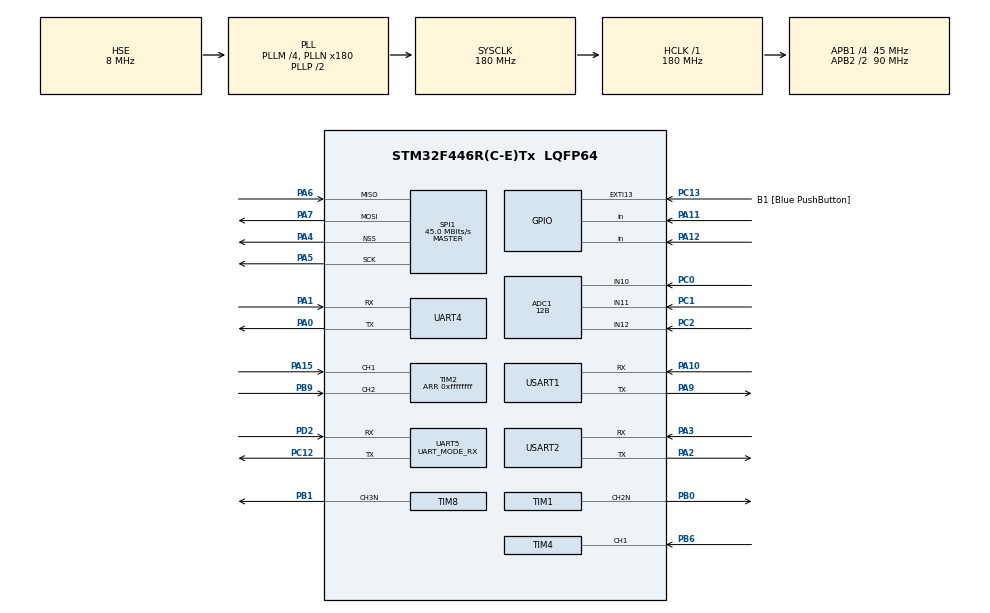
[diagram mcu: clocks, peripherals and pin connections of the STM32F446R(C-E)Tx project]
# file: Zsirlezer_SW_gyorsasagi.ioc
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ADC1.Channel-0\#ChannelRegularConversion=ADC_CHANNEL_10
ADC1.ClockPrescaler=ADC_CLOCK_SYNC_PCLK_DIV4
ADC1.ContinuousConvMode=DISABLE
ADC1.DMAContinuousRequests=ENABLE
ADC1.DataAlign=ADC_DATAALIGN_RIGHT
ADC1.DiscontinuousConvMode=DISABLE
ADC1.EOCSelection=ADC_EOC_SINGLE_CONV
ADC1.EnableAnalogWatchDog=false
ADC1.ExternalTrigConvEdge=ADC_EXTERNALTRIGCONVEDGE_NONE
ADC1.InjNumberOfConversion=0
ADC1.NbrOfConversion=1
ADC1.NbrOfConversionFlag=1
ADC1.Rank-0\#ChannelRegularConversion=1
ADC1.Resolution=ADC_RESOLUTION_12B
ADC1.SamplingTime-0\#ChannelRegularConversion=ADC_SAMPLETIME_15CYCLES
ADC1.ScanConvMode=ENABLE
ADC1.master=1
Dma.ADC1.3.Direction=DMA_PERIPH_TO_MEMORY
Dma.ADC1.3.FIFOMode=DMA_FIFOMODE_DISABLE
Dma.ADC1.3.Instance=DMA2_Stream0
Dma.ADC1.3.MemDataAlignment=DMA_MDATAALIGN_HALFWORD
Dma.ADC1.3.MemInc=DMA_MINC_ENABLE
Dma.ADC1.3.Mode=DMA_CIRCULAR
Dma.ADC1.3.PeriphDataAlignment=DMA_PDATAALIGN_HALFWORD
Dma.ADC1.3.PeriphInc=DMA_PINC_DISABLE
Dma.ADC1.3.Priority=DMA_PRIORITY_LOW
Dma.Request0=UART5_RX
Dma.Request1=USART1_RX
Dma.Request2=USART1_TX
Dma.Request3=ADC1
Dma.Request4=USART2_TX
Dma.UART5_RX.0.Direction=DMA_PERIPH_TO_MEMORY
Dma.UART5_RX.0.FIFOMode=DMA_FIFOMODE_DISABLE
Dma.UART5_RX.0.Instance=DMA1_Stream0
Dma.UART5_RX.0.MemDataAlignment=DMA_MDATAALIGN_BYTE
Dma.UART5_RX.0.MemInc=DMA_MINC_ENABLE
Dma.UART5_RX.0.Mode=DMA_CIRCULAR
Dma.UART5_RX.0.PeriphDataAlignment=DMA_PDATAALIGN_BYTE
Dma.UART5_RX.0.PeriphInc=DMA_PINC_DISABLE
Dma.UART5_RX.0.Priority=DMA_PRIORITY_LOW
Dma.USART1_RX.1.Direction=DMA_PERIPH_TO_MEMORY
Dma.USART1_RX.1.FIFOMode=DMA_FIFOMODE_DISABLE
Dma.USART1_RX.1.Instance=DMA2_Stream2
Dma.USART1_RX.1.MemDataAlignment=DMA_MDATAALIGN_BYTE
Dma.USART1_RX.1.MemInc=DMA_MINC_ENABLE
Dma.USART1_RX.1.Mode=DMA_CIRCULAR
Dma.USART1_RX.1.PeriphDataAlignment=DMA_PDATAALIGN_BYTE
Dma.USART1_RX.1.PeriphInc=DMA_PINC_DISABLE
Dma.USART1_RX.1.Priority=DMA_PRIORITY_LOW
Dma.USART1_TX.2.Direction=DMA_MEMORY_TO_PERIPH
Dma.USART1_TX.2.FIFOMode=DMA_FIFOMODE_DISABLE
Dma.USART1_TX.2.Instance=DMA2_Stream7
Dma.USART1_TX.2.MemDataAlignment=DMA_MDATAALIGN_BYTE
Dma.USART1_TX.2.MemInc=DMA_MINC_ENABLE
Dma.USART1_TX.2.Mode=DMA_NORMAL
Dma.USART1_TX.2.PeriphDataAlignment=DMA_PDATAALIGN_BYTE
Dma.USART1_TX.2.PeriphInc=DMA_PINC_DISABLE
Dma.USART1_TX.2.Priority=DMA_PRIORITY_LOW
Dma.USART2_TX.4.Direction=DMA_MEMORY_TO_PERIPH
Dma.USART2_TX.4.FIFOMode=DMA_FIFOMODE_DISABLE
Dma.USART2_TX.4.Instance=DMA1_Stream6
Dma.USART2_TX.4.MemDataAlignment=DMA_MDATAALIGN_BYTE
Dma.USART2_TX.4.MemInc=DMA_MINC_ENABLE
Dma.USART2_TX.4.Mode=DMA_NORMAL
Dma.USART2_TX.4.PeriphDataAlignment=DMA_PDATAALIGN_BYTE
Dma.USART2_TX.4.PeriphInc=DMA_PINC_DISABLE
Dma.USART2_TX.4.Priority=DMA_PRIORITY_LOW
Mcu.Family=STM32F4
Mcu.Name=STM32F446R(C-E)Tx
Mcu.Package=LQFP64
NVIC.DMA1_Stream0_IRQn=true\:0\:0\:false\:false\:true
NVIC.DMA1_Stream6_IRQn=true\:0\:0\:false\:false\:true
NVIC.DMA2_Stream0_IRQn=true\:0\:0\:false\:false\:true
NVIC.DMA2_Stream2_IRQn=true\:0\:0\:false\:false\:true
NVIC.DMA2_Stream7_IRQn=true\:0\:0\:false\:false\:true
NVIC.PriorityGroup=NVIC_PRIORITYGROUP_0
NVIC.TIM4_IRQn=true\:0\:0\:false\:false\:true
NVIC.TIM6_DAC_IRQn=true\:0\:0\:false\:false\:true
NVIC.TIM7_IRQn=true\:0\:0\:false\:false\:true
NVIC.UART4_IRQn=true\:0\:0\:false\:false\:true
NVIC.UART5_IRQn=true\:0\:0\:false\:false\:true
NVIC.USART1_IRQn=true\:0\:0\:false\:false\:true
NVIC.USART2_IRQn=true\:0\:0\:false\:false\:true
PA0-WKUP.Mode=Asynchronous
PA0-WKUP.Signal=UART4_TX
PA1.Mode=Asynchronous
PA1.Signal=UART4_RX
PA10.Mode=Asynchronous
PA10.Signal=USART1_RX
PA11.Signal=GPIO_Input
PA12.Signal=GPIO_Input
PA13.GPIO_Label=TMS
PA13.Signal=SYS_JTMS-SWDIO
PA14.GPIO_Label=TCK
PA14.Signal=SYS_JTCK-SWCLK
PA15.Signal=S_TIM2_CH1_ETR
PA2.Mode=Asynchronous
PA2.Signal=USART2_TX
PA3.Mode=Asynchronous
PA3.Signal=USART2_RX
PA4.Mode=NSS_Signal_Hard_Output
PA4.Signal=SPI1_NSS
PA5.Mode=Full_Duplex_Master
PA5.Signal=SPI1_SCK
PA6.Mode=Full_Duplex_Master
PA6.Signal=SPI1_MISO
PA7.Mode=Full_Duplex_Master
PA7.Signal=SPI1_MOSI
PA9.Mode=Asynchronous
PA9.Signal=USART1_TX
PB0.GPIO_ModeDefaultPP=GPIO_MODE_AF_PP
PB0.Mode=PWM Generation2 CH2N
PB0.Signal=TIM1_CH2N
PB1.Mode=PWM Generation3 CH3N
PB1.Signal=TIM8_CH3N
PB3.GPIO_Label=SWO
PB3.Signal=SYS_JTDO-SWO
PB6.Signal=S_TIM4_CH1
PB9.Signal=S_TIM2_CH2
PC0.Signal=ADCx_IN10
PC1.Signal=ADCx_IN11
PC12.Mode=Asynchronous
PC12.Signal=UART5_TX
PC13.GPIO_Label=B1 [Blue PushButton]
PC13.GPIO_ModeDefaultEXTI=GPIO_MODE_EVT_RISING
PC13.Signal=GPXTI13
PC2.Signal=ADCx_IN12
PD2.Mode=Asynchronous
PD2.Signal=UART5_RX
PH0-OSC_IN.Mode=HSE-External-Oscillator
PH0-OSC_IN.Signal=RCC_OSC_IN
PH1-OSC_OUT.Mode=HSE-External-Oscillator
PH1-OSC_OUT.Signal=RCC_OSC_OUT
ProjectManager.HeapSize=0x200
ProjectManager.StackSize=0x400
ProjectManager.TargetToolchain=SW4STM32
RCC.AHBFreq_Value=180000000
RCC.APB1CLKDivider=RCC_HCLK_DIV4
RCC.APB1Freq_Value=45000000
RCC.APB1TimFreq_Value=90000000
RCC.APB2CLKDivider=RCC_HCLK_DIV2
RCC.APB2Freq_Value=90000000
RCC.APB2TimFreq_Value=180000000
RCC.CortexFreq_Value=180000000
RCC.FLatency-AdvancedSettings=FLASH_LATENCY_5
RCC.HCLKFreq_Value=180000000
RCC.HSE_VALUE=8000000
RCC.HSI_VALUE=16000000
RCC.LSE_VALUE=32768
RCC.PLLM=4
RCC.PLLN=180
RCC.PLLSourceVirtual=RCC_PLLSOURCE_HSE
RCC.SYSCLKFreq_VALUE=180000000
RCC.SYSCLKSource=RCC_SYSCLKSOURCE_PLLCLK
RCC.USBFreq_Value=180000000
RCC.VCOOutputFreq_Value=360000000
SH.ADCx_IN10.0=ADC1_IN10,IN10
SH.ADCx_IN11.0=ADC1_IN11,IN11
SH.ADCx_IN12.0=ADC1_IN12,IN12
SH.S_TIM2_CH1_ETR.0=TIM2_CH1,Encoder_Interface
SH.S_TIM2_CH2.0=TIM2_CH2,Encoder_Interface
SH.S_TIM4_CH1.0=TIM4_CH1,Input_Capture1_from_TI1
SPI1.CalculateBaudRate=45.0 MBits/s
SPI1.Mode=SPI_MODE_MASTER
SPI1.VirtualNSS=VM_NSSHARD
TIM1.Channel-PWM\ Generation2\ CH2N=TIM_CHANNEL_2
TIM1.Period=64614
TIM1.Prescaler=38
TIM1.Pulse-PWM\ Generation2\ CH2N=7497
TIM2.Period=0xffffffff
TIM4.ICPolarity_CH1=TIM_INPUTCHANNELPOLARITY_BOTHEDGE
TIM4.Period=64614
TIM4.Prescaler=38
TIM6.Period=65454
TIM6.Prescaler=65
TIM7.Period=9999
TIM7.Prescaler=89
TIM8.Channel-PWM\ Generation3\ CH3N=TIM_CHANNEL_3
TIM8.Period=64614
TIM8.Prescaler=38
TIM8.Pulse-PWM\ Generation3\ CH3N=6932
UART5.Mode=UART_MODE_RX
VP_TIM6_VS_ClockSourceINT.Mode=Enable_Timer
VP_TIM7_VS_ClockSourceINT.Mode=Enable_Timer
board=NUCLEO-F446RE

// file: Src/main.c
/**
  ******************************************************************************
  * File Name          : main.c
  * Description        : Main program body
  ******************************************************************************
  *
  * COPYRIGHT(c) 2017 STMicroelectronics
  *
  * Redistribution and use in source and binary forms, with or without modification,
  * are permitted provided that the following conditions are met:
  *   1. Redistributions of source code must retain the above copyright notice,
  *      this list of conditions and the following disclaimer.
  *   2. Redistributions in binary form must reproduce the above copyright notice,
  *      this list of conditions and the following disclaimer in the documentation
  *      and/or other materials provided with the distribution.
  *   3. Neither the name of STMicroelectronics nor the names of its contributors
  *      may be used to endorse or promote products derived from this software
  *      without specific prior written permission.
  *
  * THIS SOFTWARE IS PROVIDED BY THE COPYRIGHT HOLDERS AND CONTRIBUTORS "AS IS"
  * AND ANY EXPRESS OR IMPLIED WARRANTIES, INCLUDING, BUT NOT LIMITED TO, THE
  * IMPLIED WARRANTIES OF MERCHANTABILITY AND FITNESS FOR A PARTICULAR PURPOSE ARE
  * DISCLAIMED. IN NO EVENT SHALL THE COPYRIGHT HOLDER OR CONTRIBUTORS BE LIABLE
  * FOR ANY DIRECT, INDIRECT, INCIDENTAL, SPECIAL, EXEMPLARY, OR CONSEQUENTIAL
  * DAMAGES (INCLUDING, BUT NOT LIMITED TO, PROCUREMENT OF SUBSTITUTE GOODS OR
  * SERVICES; LOSS OF USE, DATA, OR PROFITS; OR BUSINESS INTERRUPTION) HOWEVER
  * CAUSED AND ON ANY THEORY OF LIABILITY, WHETHER IN CONTRACT, STRICT LIABILITY,
  * OR TORT (INCLUDING NEGLIGENCE OR OTHERWISE) ARISING IN ANY WAY OUT OF THE USE
  * OF THIS SOFTWARE, EVEN IF ADVISED OF THE POSSIBILITY OF SUCH DAMAGE.
  *
  ******************************************************************************
  */
#include "main.h"
#include "stm32f4xx_hal.h"
#include "adc.h"
#include "dma.h"
#include "spi.h"
#include "tim.h"
#include "usart.h"
#include "gpio.h"
#include "math.h"

/* USER CODE BEGIN Includes */
#include "stdbool.h"

//Defineok
//Vonalszam
#define NINCSVONAL 10
#define EGYVONAL 1
#define KETVONAL 2
#define HAROMVONAL 3
#define VONALHIBA 15

//Vonalobjektumok
#define GYORSITO 5
#define LASSITO 6
#define SIMA_VEZETOVONAL 13

//Sebszab
#define MEREDEKSEG_GYORSITASNAL 2000
#define MEREDEKSEG_LASSITASNAL 2000
#define ALAPJEL_MEREDEKSEG_GYORSITASNAL 3000
#define ALAPJEL_MEREDEKSEG_LASSITASNAL 3000

//Allapotteres szabalyozok
#define NORMAL 1
#define GYORSITO_SZAB 2

#define ELSOKOR 1
#define MASODIKKOR 2
#define HARMADIKKOR 3

/* USER CODE END Includes */

/* USER CODE BEGIN PV */
/* Private variables ---------------------------------------------------------*/

float atan_lut[5400] = {
	 -2233.6111,
	 -2233.155, -2232.6986, -2232.2421, -2231.7854, -2231.3285, -2230.8714, -2230.414, -2229.9565, -2229.4988, -2229.0408,
	 -2228.5827, -2228.1243, -2227.6658, -2227.207, -2226.7481, -2226.2889, -2225.8295, -2225.3699, -2224.9102, -2224.4502,
	 -2223.99, -2223.5296, -2223.069, -2222.6082, -2222.1471, -2221.6859, -2221.2245, -2220.7628, -2220.301, -2219.839,
	 -2219.3767, -2218.9142, -2218.4516, -2217.9887, -2217.5256, -2217.0623, -2216.5988, -2216.1351, -2215.6712, -2215.2071,
	 -2214.7428, -2214.2782, -2213.8135, -2213.3486, -2212.8834, -2212.418, -2211.9525, -2211.4867, -2211.0207, -2210.5545,
	 -2210.0881, -2209.6215, -2209.1546, -2208.6876, -2208.2204, -2207.7529, -2207.2852, -2206.8174, -2206.3493, -2205.881,
	 -2205.4125, -2204.9438, -2204.4749, -2204.0057, -2203.5364, -2203.0669, -2202.5971, -2202.1271, -2201.6569, -2201.1866,
	 -2200.7159, -2200.2451, -2199.7741, -2199.3029, -2198.8314, -2198.3598, -2197.8879, -2197.4158, -2196.9435, -2196.471,
	 -2195.9983, -2195.5254, -2195.0522, -2194.5789, -2194.1053, -2193.6315, -2193.1575, -2192.6833, -2192.2089, -2191.7343,
	 -2191.2594, -2190.7844, -2190.3091, -2189.8336, -2189.3579, -2188.882, -2188.4059, -2187.9296, -2187.453, -2186.9763,
	 -2186.4993, -2186.0221, -2185.5447, -2185.0671, -2184.5892, -2184.1112, -2183.6329, -2183.1544, -2182.6757, -2182.1968,
	 -2181.7177, -2181.2384, -2180.7588, -2180.279, -2179.799, -2179.3188, -2178.8384, -2178.3578, -2177.8769, -2177.3959,
	 -2176.9146, -2176.4331, -2175.9514, -2175.4694, -2174.9873, -2174.5049, -2174.0223, -2173.5395, -2173.0565, -2172.5733,
	 -2172.0898, -2171.6062, -2171.1223, -2170.6382, -2170.1538, -2169.6693, -2169.1845, -2168.6996, -2168.2144, -2167.729,
	 -2167.2433, -2166.7575, -2166.2714, -2165.7851, -2165.2986, -2164.8119, -2164.3249, -2163.8378, -2163.3504, -2162.8628,
	 -2162.375, -2161.8869, -2161.3986, -2160.9102, -2160.4215, -2159.9325, -2159.4434, -2158.954, -2158.4644, -2157.9746,
	 -2157.4846, -2156.9944, -2156.5039, -2156.0132, -2155.5223, -2155.0312, -2154.5398, -2154.0482, -2153.5564, -2153.0644,
	 -2152.5722, -2152.0797, -2151.587, -2151.0941, -2150.601, -2150.1076, -2149.6141, -2149.1203, -2148.6263, -2148.132,
	 -2147.6375, -2147.1429, -2146.6479, -2146.1528, -2145.6574, -2145.1619, -2144.6661, -2144.17, -2143.6738, -2143.1773,
	 -2142.6806, -2142.1837, -2141.6865, -2141.1891, -2140.6915, -2140.1937, -2139.6957, -2139.1974, -2138.6989, -2138.2002,
	 -2137.7012, -2137.2021, -2136.7027, -2136.203, -2135.7032, -2135.2031, -2134.7028, -2134.2023, -2133.7015, -2133.2005,
	 -2132.6993, -2132.1979, -2131.6962, -2131.1943, -2130.6922, -2130.1899, -2129.6873, -2129.1845, -2128.6815, -2128.1782,
	 -2127.6748, -2127.1711, -2126.6671, -2126.163, -2125.6586, -2125.154, -2124.6491, -2124.144, -2123.6387, -2123.1332,
	 -2122.6274, -2122.1215, -2121.6152, -2121.1088, -2120.6021, -2120.0952, -2119.5881, -2119.0807, -2118.5731, -2118.0653,
	 -2117.5572, -2117.049, -2116.5404, -2116.0317, -2115.5227, -2115.0135, -2114.5041, -2113.9944, -2113.4845, -2112.9744,
	 -2112.464, -2111.9534, -2111.4426, -2110.9316, -2110.4203, -2109.9088, -2109.397, -2108.8851, -2108.3728, -2107.8604,
	 -2107.3477, -2106.8348, -2106.3217, -2105.8083, -2105.2947, -2104.7809, -2104.2668, -2103.7525, -2103.238, -2102.7232,
	 -2102.2082, -2101.693, -2101.1775, -2100.6618, -2100.1459, -2099.6297, -2099.1133, -2098.5967, -2098.0798, -2097.5627,
	 -2097.0453, -2096.5278, -2096.01, -2095.4919, -2094.9736, -2094.4551, -2093.9364, -2093.4174, -2092.8982, -2092.3787,
	 -2091.859, -2091.3391, -2090.8189, -2090.2985, -2089.7779, -2089.257, -2088.7359, -2088.2146, -2087.693, -2087.1712,
	 -2086.6491, -2086.1268, -2085.6043, -2085.0815, -2084.5585, -2084.0353, -2083.5118, -2082.9881, -2082.4642, -2081.94,
	 -2081.4155, -2080.8909, -2080.366, -2079.8408, -2079.3154, -2078.7898, -2078.264, -2077.7379, -2077.2115, -2076.685,
	 -2076.1582, -2075.6311, -2075.1038, -2074.5763, -2074.0485, -2073.5205, -2072.9923, -2072.4638, -2071.935, -2071.4061,
	 -2070.8769, -2070.3474, -2069.8177, -2069.2878, -2068.7576, -2068.2272, -2067.6965, -2067.1657, -2066.6345, -2066.1031,
	 -2065.5715, -2065.0397, -2064.5076, -2063.9752, -2063.4426, -2062.9098, -2062.3767, -2061.8434, -2061.3099, -2060.7761,
	 -2060.242, -2059.7077, -2059.1732, -2058.6385, -2058.1034, -2057.5682, -2057.0327, -2056.497, -2055.961, -2055.4247,
	 -2054.8883, -2054.3516, -2053.8146, -2053.2774, -2052.7399, -2052.2023, -2051.6643, -2051.1261, -2050.5877, -2050.049,
	 -2049.5101, -2048.971, -2048.4316, -2047.8919, -2047.352, -2046.8119, -2046.2715, -2045.7309, -2045.19, -2044.6488,
	 -2044.1075, -2043.5659, -2043.024, -2042.4819, -2041.9395, -2041.3969, -2040.8541, -2040.311, -2039.7676, -2039.224,
	 -2038.6802, -2038.1361, -2037.5918, -2037.0472, -2036.5024, -2035.9573, -2035.412, -2034.8664, -2034.3206, -2033.7745,
	 -2033.2282, -2032.6816, -2032.1348, -2031.5877, -2031.0404, -2030.4929, -2029.9451, -2029.397, -2028.8487, -2028.3001,
	 -2027.7513, -2027.2023, -2026.6529, -2026.1034, -2025.5536, -2025.0035, -2024.4532, -2023.9027, -2023.3518, -2022.8008,
	 -2022.2495, -2021.6979, -2021.1461, -2020.594, -2020.0417, -2019.4891, -2018.9363, -2018.3833, -2017.8299, -2017.2764,
	 -2016.7225, -2016.1684, -2015.6141, -2015.0595, -2014.5047, -2013.9496, -2013.3943, -2012.8387, -2012.2828, -2011.7267,
	 -2011.1704, -2010.6138, -2010.0569, -2009.4998, -2008.9424, -2008.3848, -2007.8269, -2007.2688, -2006.7104, -2006.1518,
	 -2005.5929, -2005.0337, -2004.4743, -2003.9147, -2003.3548, -2002.7946, -2002.2342, -2001.6735, -2001.1126, -2000.5514,
	 -1999.99, -1999.4283, -1998.8663, -1998.3041, -1997.7416, -1997.1789, -1996.6159, -1996.0527, -1995.4892, -1994.9255,
	 -1994.3614, -1993.7972, -1993.2327, -1992.6679, -1992.1029, -1991.5376, -1990.972, -1990.4062, -1989.8402, -1989.2738,
	 -1988.7073, -1988.1404, -1987.5733, -1987.006, -1986.4384, -1985.8705, -1985.3024, -1984.734, -1984.1653, -1983.5964,
	 -1983.0273, -1982.4578, -1981.8882, -1981.3182, -1980.748, -1980.1775, -1979.6068, -1979.0358, -1978.4646, -1977.8931,
	 -1977.3213, -1976.7493, -1976.177, -1975.6045, -1975.0317, -1974.4586, -1973.8853, -1973.3117, -1972.7379, -1972.1637,
	 -1971.5894, -1971.0147, -1970.4398, -1969.8647, -1969.2893, -1968.7136, -1968.1376, -1967.5614, -1966.985, -1966.4082,
	 -1965.8312, -1965.254, -1964.6765, -1964.0987, -1963.5206, -1962.9423, -1962.3638, -1961.7849, -1961.2058, -1960.6265,
	 -1960.0468, -1959.467, -1958.8868, -1958.3064, -1957.7257, -1957.1447, -1956.5635, -1955.9821, -1955.4003, -1954.8183,
	 -1954.236, -1953.6535, -1953.0707, -1952.4876, -1951.9043, -1951.3207, -1950.7368, -1950.1527, -1949.5683, -1948.9836,
	 -1948.3987, -1947.8135, -1947.2281, -1946.6423, -1946.0563, -1945.4701, -1944.8835, -1944.2967, -1943.7097, -1943.1223,
	 -1942.5347, -1941.9469, -1941.3587, -1940.7703, -1940.1817, -1939.5927, -1939.0035, -1938.4141, -1937.8243, -1937.2343,
	 -1936.644, -1936.0535, -1935.4627, -1934.8716, -1934.2802, -1933.6886, -1933.0967, -1932.5045, -1931.9121, -1931.3194,
	 -1930.7264, -1930.1332, -1929.5397, -1928.9459, -1928.3519, -1927.7575, -1927.1629, -1926.5681, -1925.9729, -1925.3775,
	 -1924.7819, -1924.1859, -1923.5897, -1922.9932, -1922.3964, -1921.7994, -1921.2021, -1920.6045, -1920.0067, -1919.4086,
	 -1918.8102, -1918.2115, -1917.6126, -1917.0134, -1916.4139, -1915.8141, -1915.2141, -1914.6138, -1914.0132, -1913.4124,
	 -1912.8112, -1912.2098, -1911.6082, -1911.0062, -1910.404, -1909.8015, -1909.1988, -1908.5957, -1907.9924, -1907.3888,
	 -1906.785, -1906.1808, -1905.5764, -1904.9717, -1904.3668, -1903.7615, -1903.156, -1902.5503, -1901.9442, -1901.3379,
	 -1900.7312, -1900.1244, -1899.5172, -1898.9097, -1898.302, -1897.694, -1897.0858, -1896.4772, -1895.8684, -1895.2593,
	 -1894.6499, -1894.0403, -1893.4303, -1892.8201, -1892.2097, -1891.5989, -1890.9879, -1890.3765, -1889.7649, -1889.1531,
	 -1888.5409, -1887.9285, -1887.3158, -1886.7028, -1886.0895, -1885.476, -1884.8622, -1884.2481, -1883.6337, -1883.019,
	 -1882.4041, -1881.7889, -1881.1734, -1880.5576, -1879.9415, -1879.3252, -1878.7086, -1878.0917, -1877.4745, -1876.8571,
	 -1876.2393, -1875.6213, -1875.003, -1874.3844, -1873.7656, -1873.1464, -1872.527, -1871.9073, -1871.2873, -1870.6671,
	 -1870.0465, -1869.4257, -1868.8046, -1868.1832, -1867.5615, -1866.9395, -1866.3173, -1865.6948, -1865.072, -1864.4489,
	 -1863.8255, -1863.2019, -1862.5779, -1861.9537, -1861.3292, -1860.7044, -1860.0794, -1859.454, -1858.8284, -1858.2025,
	 -1857.5763, -1856.9498, -1856.323, -1855.696, -1855.0686, -1854.441, -1853.8131, -1853.1849, -1852.5564, -1851.9277,
	 -1851.2986, -1850.6693, -1850.0397, -1849.4098, -1848.7796, -1848.1491, -1847.5183, -1846.8873, -1846.256, -1845.6243,
	 -1844.9924, -1844.3603, -1843.7278, -1843.095, -1842.462, -1841.8286, -1841.195, -1840.5611, -1839.9269, -1839.2924,
	 -1838.6576, -1838.0226, -1837.3872, -1836.7516, -1836.1157, -1835.4795, -1834.843, -1834.2062, -1833.5691, -1832.9318,
	 -1832.2941, -1831.6562, -1831.0179, -1830.3794, -1829.7406, -1829.1015, -1828.4621, -1827.8225, -1827.1825, -1826.5422,
	 -1825.9017, -1825.2609, -1824.6198, -1823.9783, -1823.3366, -1822.6947, -1822.0524, -1821.4098, -1820.7669, -1820.1238,
	 -1819.4803, -1818.8366, -1818.1926, -1817.5483, -1816.9037, -1816.2588, -1815.6136, -1814.9681, -1814.3223, -1813.6762,
	 -1813.0299, -1812.3832, -1811.7363, -1811.0891, -1810.4415, -1809.7937, -1809.1456, -1808.4972, -1807.8485, -1807.1995,
	 -1806.5502, -1805.9007, -1805.2508, -1804.6006, -1803.9502, -1803.2994, -1802.6484, -1801.9971, -1801.3454, -1800.6935,
	 -1800.0413, -1799.3888, -1798.736, -1798.0829, -1797.4295, -1796.7758, -1796.1218, -1795.4675, -1794.813, -1794.1581,
	 -1793.5029, -1792.8475, -1792.1917, -1791.5357, -1790.8793, -1790.2227, -1789.5657, -1788.9085, -1788.251, -1787.5931,
	 -1786.935, -1786.2766, -1785.6179, -1784.9589, -1784.2996, -1783.64, -1782.9801, -1782.3199, -1781.6594, -1780.9986,
	 -1780.3375, -1779.6761, -1779.0144, -1778.3524, -1777.6901, -1777.0276, -1776.3647, -1775.7015, -1775.038, -1774.3743,
	 -1773.7102, -1773.0458, -1772.3811, -1771.7162, -1771.0509, -1770.3854, -1769.7195, -1769.0533, -1768.3869, -1767.7201,
	 -1767.053, -1766.3857, -1765.718, -1765.0501, -1764.3818, -1763.7132, -1763.0444, -1762.3752, -1761.7057, -1761.036,
	 -1760.3659, -1759.6956, -1759.0249, -1758.3539, -1757.6827, -1757.0111, -1756.3392, -1755.667, -1754.9946, -1754.3218,
	 -1753.6487, -1752.9753, -1752.3017, -1751.6277, -1750.9534, -1750.2788, -1749.6039, -1748.9287, -1748.2532, -1747.5774,
	 -1746.9013, -1746.2249, -1745.5482, -1744.8712, -1744.1939, -1743.5163, -1742.8384, -1742.1602, -1741.4816, -1740.8028,
	 -1740.1237, -1739.4442, -1738.7645, -1738.0845, -1737.4041, -1736.7235, -1736.0425, -1735.3612, -1734.6797, -1733.9978,
	 -1733.3156, -1732.6331, -1731.9504, -1731.2673, -1730.5839, -1729.9002, -1729.2162, -1728.5318, -1727.8472, -1727.1623,
	 -1726.4771, -1725.7915, -1725.1057, -1724.4195, -1723.7331, -1723.0463, -1722.3593, -1721.6719, -1720.9842, -1720.2962,
	 -1719.6079, -1718.9193, -1718.2304, -1717.5412, -1716.8517, -1716.1618, -1715.4717, -1714.7812, -1714.0905, -1713.3994,
	 -1712.7081, -1712.0164, -1711.3244, -1710.6321, -1709.9395, -1709.2466, -1708.5534, -1707.8598, -1707.166, -1706.4718,
	 -1705.7774, -1705.0826, -1704.3875, -1703.6922, -1702.9965, -1702.3005, -1701.6042, -1700.9075, -1700.2106, -1699.5134,
	 -1698.8158, -1698.118, -1697.4198, -1696.7213, -1696.0225, -1695.3234, -1694.624, -1693.9243, -1693.2242, -1692.5239,
	 -1691.8232, -1691.1223, -1690.421, -1689.7194, -1689.0175, -1688.3153, -1687.6128, -1686.9099, -1686.2068, -1685.5033,
	 -1684.7995, -1684.0955, -1683.3911, -1682.6864, -1681.9813, -1681.276, -1680.5704, -1679.8644, -1679.1581, -1678.4516,
	 -1677.7447, -1677.0374, -1676.3299, -1675.6221, -1674.9139, -1674.2055, -1673.4967, -1672.7876, -1672.0782, -1671.3685,
	 -1670.6585, -1669.9481, -1669.2375, -1668.5265, -1667.8152, -1667.1036, -1666.3917, -1665.6795, -1664.9669, -1664.2541,
	 -1663.5409, -1662.8274, -1662.1136, -1661.3995, -1660.685, -1659.9703, -1659.2552, -1658.5398, -1657.8241, -1657.1081,
	 -1656.3918, -1655.6752, -1654.9582, -1654.2409, -1653.5233, -1652.8054, -1652.0872, -1651.3687, -1650.6498, -1649.9306,
	 -1649.2112, -1648.4913, -1647.7712, -1647.0508, -1646.33, -1645.609, -1644.8876, -1644.1659, -1643.4438, -1642.7215,
	 -1641.9988, -1641.2758, -1640.5525, -1639.8289, -1639.105, -1638.3807, -1637.6562, -1636.9313, -1636.2061, -1635.4806,
	 -1634.7547, -1634.0286, -1633.3021, -1632.5753, -1631.8482, -1631.1207, -1630.393, -1629.6649, -1628.9365, -1628.2078,
	 -1627.4788, -1626.7494, -1626.0197, -1625.2898, -1624.5594, -1623.8288, -1623.0979, -1622.3666, -1621.635, -1620.9031,
	 -1620.1709, -1619.4383, -1618.7055, -1617.9723, -1617.2388, -1616.5049, -1615.7708, -1615.0363, -1614.3015, -1613.5664,
	 -1612.8309, -1612.0952, -1611.3591, -1610.6227, -1609.886, -1609.1489, -1608.4116, -1607.6739, -1606.9359, -1606.1976,
	 -1605.4589, -1604.7199, -1603.9806, -1603.241, -1602.5011, -1601.7608, -1601.0202, -1600.2793, -1599.5381, -1598.7965,
	 -1598.0547, -1597.3125, -1596.57, -1595.8271, -1595.0839, -1594.3405, -1593.5966, -1592.8525, -1592.108, -1591.3633,
	 -1590.6182, -1589.8727, -1589.127, -1588.3809, -1587.6345, -1586.8878, -1586.1407, -1585.3933, -1584.6456, -1583.8976,
	 -1583.1493, -1582.4006, -1581.6516, -1580.9023, -1580.1526, -1579.4027, -1578.6524, -1577.9018, -1577.1508, -1576.3995,
	 -1575.6479, -1574.896, -1574.1438, -1573.3912, -1572.6383, -1571.8851, -1571.1316, -1570.3777, -1569.6235, -1568.869,
	 -1568.1141, -1567.3589, -1566.6034, -1565.8476, -1565.0915, -1564.335, -1563.5782, -1562.821, -1562.0636, -1561.3058,
	 -1560.5477, -1559.7892, -1559.0305, -1558.2714, -1557.512, -1556.7522, -1555.9921, -1555.2317, -1554.471, -1553.71,
	 -1552.9486, -1552.1869, -1551.4248, -1550.6625, -1549.8998, -1549.1368, -1548.3734, -1547.6097, -1546.8457, -1546.0814,
	 -1545.3167, -1544.5517, -1543.7864, -1543.0208, -1542.2548, -1541.4885, -1540.7219, -1539.9549, -1539.1876, -1538.42,
	 -1537.6521, -1536.8838, -1536.1152, -1535.3463, -1534.577, -1533.8074, -1533.0375, -1532.2673, -1531.4967, -1530.7258,
	 -1529.9545, -1529.183, -1528.4111, -1527.6389, -1526.8663, -1526.0934, -1525.3202, -1524.5467, -1523.7728, -1522.9986,
	 -1522.2241, -1521.4492, -1520.674, -1519.8985, -1519.1226, -1518.3465, -1517.5699, -1516.7931, -1516.0159, -1515.2384,
	 -1514.4606, -1513.6824, -1512.9039, -1512.1251, -1511.3459, -1510.5664, -1509.7866, -1509.0065, -1508.226, -1507.4452,
	 -1506.664, -1505.8825, -1505.1007, -1504.3186, -1503.5361, -1502.7533, -1501.9702, -1501.1867, -1500.4029, -1499.6188,
	 -1498.8343, -1498.0495, -1497.2644, -1496.4789, -1495.6931, -1494.907, -1494.1206, -1493.3338, -1492.5467, -1491.7592,
	 -1490.9714, -1490.1833, -1489.3948, -1488.6061, -1487.8169, -1487.0275, -1486.2377, -1485.4476, -1484.6572, -1483.8664,
	 -1483.0753, -1482.2838, -1481.492, -1480.6999, -1479.9075, -1479.1147, -1478.3216, -1477.5281, -1476.7344, -1475.9403,
	 -1475.1458, -1474.351, -1473.5559, -1472.7605, -1471.9647, -1471.1686, -1470.3721, -1469.5753, -1468.7782, -1467.9808,
	 -1467.183, -1466.3849, -1465.5864, -1464.7876, -1463.9885, -1463.1891, -1462.3893, -1461.5891, -1460.7887, -1459.9879,
	 -1459.1868, -1458.3853, -1457.5835, -1456.7814, -1455.9789, -1455.1761, -1454.373, -1453.5695, -1452.7657, -1451.9616,
	 -1451.1571, -1450.3523, -1449.5471, -1448.7417, -1447.9358, -1447.1297, -1446.3232, -1445.5164, -1444.7092, -1443.9017,
	 -1443.0939, -1442.2857, -1441.4772, -1440.6684, -1439.8592, -1439.0497, -1438.2399, -1437.4297, -1436.6192, -1435.8084,
	 -1434.9972, -1434.1857, -1433.3738, -1432.5616, -1431.7491, -1430.9362, -1430.123, -1429.3095, -1428.4956, -1427.6814,
	 -1426.8669, -1426.052, -1425.2368, -1424.4212, -1423.6053, -1422.7891, -1421.9725, -1421.1556, -1420.3384, -1419.5208,
	 -1418.7029, -1417.8847, -1417.0661, -1416.2472, -1415.4279, -1414.6083, -1413.7884, -1412.9681, -1412.1475, -1411.3266,
	 -1410.5053, -1409.6837, -1408.8617, -1408.0395, -1407.2168, -1406.3939, -1405.5706, -1404.7469, -1403.923, -1403.0986,
	 -1402.274, -1401.449, -1400.6237, -1399.798, -1398.972, -1398.1457, -1397.319, -1396.492, -1395.6647, -1394.837,
	 -1394.009, -1393.1806, -1392.3519, -1391.5229, -1390.6935, -1389.8638, -1389.0338, -1388.2034, -1387.3726, -1386.5416,
	 -1385.7102, -1384.8785, -1384.0464, -1383.214, -1382.3812, -1381.5481, -1380.7147, -1379.8809, -1379.0468, -1378.2124,
	 -1377.3776, -1376.5425, -1375.7071, -1374.8713, -1374.0351, -1373.1987, -1372.3619, -1371.5247, -1370.6872, -1369.8494,
	 -1369.0113, -1368.1728, -1367.3339, -1366.4948, -1365.6552, -1364.8154, -1363.9752, -1363.1347, -1362.2938, -1361.4526,
	 -1360.6111, -1359.7692, -1358.927, -1358.0844, -1357.2415, -1356.3983, -1355.5547, -1354.7108, -1353.8666, -1353.022,
	 -1352.177, -1351.3318, -1350.4862, -1349.6402, -1348.794, -1347.9473, -1347.1004, -1346.2531, -1345.4055, -1344.5575,
	 -1343.7092, -1342.8605, -1342.0115, -1341.1622, -1340.3125, -1339.4625, -1338.6122, -1337.7615, -1336.9105, -1336.0591,
	 -1335.2074, -1334.3554, -1333.503, -1332.6503, -1331.7972, -1330.9438, -1330.0901, -1329.236, -1328.3816, -1327.5269,
	 -1326.6718, -1325.8164, -1324.9606, -1324.1045, -1323.2481, -1322.3913, -1321.5342, -1320.6767, -1319.8189, -1318.9608,
	 -1318.1023, -1317.2435, -1316.3843, -1315.5249, -1314.665, -1313.8049, -1312.9444, -1312.0835, -1311.2223, -1310.3608,
	 -1309.4989, -1308.6367, -1307.7742, -1306.9113, -1306.0481, -1305.1845, -1304.3207, -1303.4564, -1302.5918, -1301.7269,
	 -1300.8617, -1299.9961, -1299.1302, -1298.2639, -1297.3973, -1296.5304, -1295.6631, -1294.7955, -1293.9275, -1293.0592,
	 -1292.1906, -1291.3216, -1290.4523, -1289.5826, -1288.7126, -1287.8423, -1286.9716, -1286.1006, -1285.2293, -1284.3576,
	 -1283.4856, -1282.6132, -1281.7405, -1280.8675, -1279.9941, -1279.1204, -1278.2463, -1277.3719, -1276.4972, -1275.6221,
	 -1274.7467, -1273.871, -1272.9949, -1272.1185, -1271.2417, -1270.3646, -1269.4872, -1268.6094, -1267.7313, -1266.8528,
	 -1265.974, -1265.0949, -1264.2154, -1263.3356, -1262.4555, -1261.575, -1260.6942, -1259.813, -1258.9315, -1258.0497,
	 -1257.1675, -1256.285, -1255.4022, -1254.519, -1253.6354, -1252.7516, -1251.8674, -1250.9828, -1250.098, -1249.2127,
	 -1248.3272, -1247.4413, -1246.5551, -1245.6685, -1244.7816, -1243.8944, -1243.0068, -1242.1189, -1241.2306, -1240.342,
	 -1239.4531, -1238.5638, -1237.6742, -1236.7843, -1235.894, -1235.0034, -1234.1124, -1233.2212, -1232.3295, -1231.4376,
	 -1230.5453, -1229.6526, -1228.7596, -1227.8663, -1226.9727, -1226.0787, -1225.1844, -1224.2897, -1223.3947, -1222.4994,
	 -1221.6037, -1220.7077, -1219.8113, -1218.9147, -1218.0176, -1217.1203, -1216.2226, -1215.3246, -1214.4262, -1213.5275,
	 -1212.6285, -1211.7291, -1210.8294, -1209.9293, -1209.0289, -1208.1282, -1207.2272, -1206.3258, -1205.424, -1204.522,
	 -1203.6196, -1202.7168, -1201.8138, -1200.9104, -1200.0066, -1199.1025, -1198.1981, -1197.2934, -1196.3883, -1195.4828,
	 -1194.5771, -1193.671, -1192.7646, -1191.8578, -1190.9507, -1190.0433, -1189.1355, -1188.2274, -1187.3189, -1186.4102,
	 -1185.501, -1184.5916, -1183.6818, -1182.7717, -1181.8612, -1180.9505, -1180.0393, -1179.1279, -1178.2161, -1177.304,
	 -1176.3915, -1175.4787, -1174.5656, -1173.6521, -1172.7383, -1171.8242, -1170.9097, -1169.9949, -1169.0798, -1168.1643,
	 -1167.2485, -1166.3324, -1165.4159, -1164.4991, -1163.582, -1162.6645, -1161.7467, -1160.8286, -1159.9101, -1158.9913,
	 -1158.0721, -1157.1527, -1156.2329, -1155.3127, -1154.3923, -1153.4714, -1152.5503, -1151.6288, -1150.707, -1149.7849,
	 -1148.8624, -1147.9396, -1147.0165, -1146.093, -1145.1692, -1144.2451, -1143.3206, -1142.3958, -1141.4707, -1140.5453,
	 -1139.6195, -1138.6933, -1137.7669, -1136.8401, -1135.913, -1134.9855, -1134.0577, -1133.1296, -1132.2012, -1131.2724,
	 -1130.3433, -1129.4139, -1128.4841, -1127.554, -1126.6236, -1125.6928, -1124.7617, -1123.8303, -1122.8985, -1121.9664,
	 -1121.034, -1120.1013, -1119.1682, -1118.2348, -1117.3011, -1116.367, -1115.4326, -1114.4979, -1113.5628, -1112.6274,
	 -1111.6917, -1110.7557, -1109.8193, -1108.8826, -1107.9456, -1107.0082, -1106.0705, -1105.1325, -1104.1941, -1103.2555,
	 -1102.3164, -1101.3771, -1100.4374, -1099.4975, -1098.5571, -1097.6165, -1096.6755, -1095.7342, -1094.7926, -1093.8506,
	 -1092.9083, -1091.9657, -1091.0227, -1090.0795, -1089.1359, -1088.1919, -1087.2477, -1086.3031, -1085.3582, -1084.413,
	 -1083.4674, -1082.5215, -1081.5753, -1080.6288, -1079.6819, -1078.7347, -1077.7872, -1076.8393, -1075.8911, -1074.9426,
	 -1073.9938, -1073.0447, -1072.0952, -1071.1454, -1070.1952, -1069.2448, -1068.294, -1067.3429, -1066.3915, -1065.4397,
	 -1064.4876, -1063.5352, -1062.5825, -1061.6295, -1060.6761, -1059.7224, -1058.7683, -1057.814, -1056.8593, -1055.9043,
	 -1054.949, -1053.9934, -1053.0374, -1052.0811, -1051.1245, -1050.1675, -1049.2103, -1048.2527, -1047.2948, -1046.3365,
	 -1045.378, -1044.4191, -1043.4599, -1042.5004, -1041.5405, -1040.5804, -1039.6199, -1038.6591, -1037.6979, -1036.7365,
	 -1035.7747, -1034.8126, -1033.8502, -1032.8875, -1031.9244, -1030.961, -1029.9973, -1029.0333, -1028.069, -1027.1043,
	 -1026.1393, -1025.174, -1024.2084, -1023.2425, -1022.2762, -1021.3096, -1020.3427, -1019.3755, -1018.408, -1017.4401,
	 -1016.4719, -1015.5034, -1014.5346, -1013.5655, -1012.596, -1011.6262, -1010.6562, -1009.6857, -1008.715, -1007.744,
	 -1006.7726, -1005.8009, -1004.8289, -1003.8566, -1002.884, -1001.9111, -1000.9378, -999.9642, -998.9903, -998.0161,
	 -997.0416, -996.0667, -995.0916, -994.1161, -993.1403, -992.1642, -991.1878, -990.211, -989.234, -988.2566,
	 -987.2789, -986.3009, -985.3226, -984.344, -983.365, -982.3858, -981.4062, -980.4263, -979.4461, -978.4656,
	 -977.4848, -976.5036, -975.5222, -974.5404, -973.5583, -972.5759, -971.5932, -970.6102, -969.6269, -968.6433,
	 -967.6593, -966.675, -965.6905, -964.7056, -963.7204, -962.7349, -961.749, -960.7629, -959.7765, -958.7897,
	 -957.8027, -956.8153, -955.8276, -954.8396, -953.8513, -952.8627, -951.8738, -950.8845, -949.895, -948.9051,
	 -947.915, -946.9245, -945.9337, -944.9427, -943.9513, -942.9596, -941.9676, -940.9752, -939.9826, -938.9897,
	 -937.9965, -937.0029, -936.0091, -935.0149, -934.0204, -933.0257, -932.0306, -931.0352, -930.0395, -929.0435,
	 -928.0472, -927.0506, -926.0537, -925.0565, -924.059, -923.0612, -922.063, -921.0646, -920.0659, -919.0668,
	 -918.0675, -917.0678, -916.0679, -915.0676, -914.0671, -913.0662, -912.065, -911.0636, -910.0618, -909.0597,
	 -908.0574, -907.0547, -906.0517, -905.0484, -904.0449, -903.041, -902.0368, -901.0323, -900.0275, -899.0225,
	 -898.0171, -897.0114, -896.0054, -894.9991, -893.9926, -892.9857, -891.9785, -890.971, -889.9633, -888.9552,
	 -887.9468, -886.9382, -885.9292, -884.9199, -883.9104, -882.9005, -881.8903, -880.8799, -879.8691, -878.8581,
	 -877.8468, -876.8351, -875.8232, -874.811, -873.7984, -872.7856, -871.7725, -870.7591, -869.7454, -868.7314,
	 -867.7171, -866.7025, -865.6876, -864.6724, -863.657, -862.6412, -861.6252, -860.6088, -859.5922, -858.5752,
	 -857.558, -856.5405, -855.5227, -854.5046, -853.4862, -852.4675, -851.4485, -850.4293, -849.4097, -848.3899,
	 -847.3697, -846.3493, -845.3286, -844.3076, -843.2863, -842.2647, -841.2429, -840.2207, -839.1982, -838.1755,
	 -837.1525, -836.1292, -835.1056, -834.0817, -833.0575, -832.0331, -831.0083, -829.9833, -828.9579, -827.9323,
	 -826.9065, -825.8803, -824.8538, -823.8271, -822.8, -821.7727, -820.7451, -819.7172, -818.6891, -817.6606,
	 -816.6319, -815.6028, -814.5735, -813.5439, -812.5141, -811.4839, -810.4535, -809.4228, -808.3918, -807.3605,
	 -806.3289, -805.2971, -804.265, -803.2326, -802.1999, -801.1669, -800.1337, -799.1002, -798.0664, -797.0323,
	 -795.9979, -794.9633, -793.9284, -792.8932, -791.8577, -790.8219, -789.7859, -788.7496, -787.713, -786.6762,
	 -785.639, -784.6016, -783.5639, -782.526, -781.4877, -780.4492, -779.4104, -778.3714, -777.332, -776.2924,
	 -775.2525, -774.2124, -773.1719, -772.1312, -771.0902, -770.049, -769.0075, -767.9657, -766.9236, -765.8813,
	 -764.8386, -763.7958, -762.7526, -761.7092, -760.6655, -759.6215, -758.5773, -757.5328, -756.488, -755.4429,
	 -754.3976, -753.352, -752.3062, -751.2601, -750.2137, -749.167, -748.1201, -747.0729, -746.0254, -744.9777,
	 -743.9297, -742.8815, -741.8329, -740.7842, -739.7351, -738.6858, -737.6362, -736.5863, -735.5362, -734.4859,
	 -733.4352, -732.3843, -731.3331, -730.2817, -729.23, -728.1781, -727.1258, -726.0734, -725.0206, -723.9676,
	 -722.9143, -721.8608, -720.807, -719.753, -718.6987, -717.6441, -716.5893, -715.5342, -714.4789, -713.4233,
	 -712.3674, -711.3113, -710.2549, -709.1983, -708.1414, -707.0842, -706.0268, -704.9692, -703.9113, -702.8531,
	 -701.7947, -700.736, -699.677, -698.6178, -697.5584, -696.4987, -695.4387, -694.3785, -693.3181, -692.2574,
	 -691.1964, -690.1352, -689.0737, -688.012, -686.95, -685.8878, -684.8253, -683.7626, -682.6996, -681.6364,
	 -680.5729, -679.5092, -678.4452, -677.3809, -676.3165, -675.2517, -674.1868, -673.1216, -672.0561, -670.9904,
	 -669.9244, -668.8582, -667.7918, -666.7251, -665.6581, -664.5909, -663.5235, -662.4558, -661.3879, -660.3197,
	 -659.2513, -658.1826, -657.1137, -656.0446, -654.9752, -653.9056, -652.8357, -651.7656, -650.6953, -649.6247,
	 -648.5538, -647.4828, -646.4114, -645.3399, -644.2681, -643.1961, -642.1238, -641.0513, -639.9785, -638.9055,
	 -637.8323, -636.7589, -635.6852, -634.6112, -633.537, -632.4626, -631.388, -630.3131, -629.238, -628.1626,
	 -627.0871, -626.0112, -624.9352, -623.8589, -622.7824, -621.7056, -620.6286, -619.5514, -618.474, -617.3963,
	 -616.3184, -615.2402, -614.1619, -613.0832, -612.0044, -610.9253, -609.8461, -608.7665, -607.6868, -606.6068,
	 -605.5266, -604.4461, -603.3655, -602.2846, -601.2035, -600.1221, -599.0406, -597.9588, -596.8767, -595.7945,
	 -594.712, -593.6293, -592.5464, -591.4632, -590.3799, -589.2963, -588.2125, -587.1284, -586.0442, -584.9597,
	 -583.875, -582.7901, -581.7049, -580.6196, -579.534, -578.4482, -577.3621, -576.2759, -575.1894, -574.1027,
	 -573.0158, -571.9287, -570.8414, -569.7538, -568.6661, -567.5781, -566.4899, -565.4015, -564.3128, -563.224,
	 -562.1349, -561.0456, -559.9561, -558.8664, -557.7765, -556.6864, -555.5961, -554.5055, -553.4147, -552.3237,
	 -551.2326, -550.1412, -549.0495, -547.9577, -546.8657, -545.7734, -544.681, -543.5883, -542.4955, -541.4024,
	 -540.3091, -539.2156, -538.1219, -537.028, -535.9339, -534.8396, -533.745, -532.6503, -531.5554, -530.4602,
	 -529.3649, -528.2694, -527.1736, -526.0777, -524.9815, -523.8851, -522.7886, -521.6918, -520.5949, -519.4977,
	 -518.4003, -517.3028, -516.205, -515.107, -514.0089, -512.9105, -511.812, -510.7132, -509.6142, -508.5151,
	 -507.4157, -506.3162, -505.2164, -504.1165, -503.0164, -501.916, -500.8155, -499.7148, -498.6139, -497.5128,
	 -496.4115, -495.31, -494.2083, -493.1064, -492.0044, -490.9021, -489.7996, -488.697, -487.5942, -486.4911,
	 -485.3879, -484.2845, -483.1809, -482.0772, -480.9732, -479.8691, -478.7647, -477.6602, -476.5555, -475.4506,
	 -474.3455, -473.2402, -472.1348, -471.0291, -469.9233, -468.8173, -467.7111, -466.6047, -465.4982, -464.3914,
	 -463.2845, -462.1774, -461.0701, -459.9626, -458.855, -457.7472, -456.6392, -455.531, -454.4226, -453.3141,
	 -452.2054, -451.0965, -449.9874, -448.8781, -447.7687, -446.6591, -445.5493, -444.4394, -443.3292, -442.2189,
	 -441.1084, -439.9978, -438.887, -437.776, -436.6648, -435.5534, -434.4419, -433.3302, -432.2184, -431.1064,
	 -429.9942, -428.8818, -427.7692, -426.6565, -425.5437, -424.4306, -423.3174, -422.204, -421.0905, -419.9768,
	 -418.8629, -417.7488, -416.6346, -415.5203, -414.4057, -413.291, -412.1761, -411.0611, -409.9459, -408.8306,
	 -407.715, -406.5994, -405.4835, -404.3675, -403.2513, -402.135, -401.0185, -399.9019, -398.7851, -397.6681,
	 -396.551, -395.4337, -394.3163, -393.1987, -392.0809, -390.963, -389.845, -388.7268, -387.6084, -386.4899,
	 -385.3712, -384.2524, -383.1334, -382.0142, -380.8949, -379.7755, -378.6559, -377.5362, -376.4163, -375.2962,
	 -374.176, -373.0557, -371.9352, -370.8145, -369.6937, -368.5728, -367.4517, -366.3305, -365.2091, -364.0876,
	 -362.9659, -361.8441, -360.7221, -359.6, -358.4777, -357.3553, -356.2328, -355.1101, -353.9873, -352.8643,
	 -351.7412, -350.618, -349.4946, -348.371, -347.2474, -346.1235, -344.9996, -343.8755, -342.7513, -341.6269,
	 -340.5024, -339.3778, -338.253, -337.1281, -336.003, -334.8779, -333.7525, -332.6271, -331.5015, -330.3758,
	 -329.2499, -328.1239, -326.9978, -325.8716, -324.7452, -323.6187, -322.492, -321.3653, -320.2384, -319.1113,
	 -317.9842, -316.8569, -315.7295, -314.6019, -313.4742, -312.3464, -311.2185, -310.0905, -308.9623, -307.834,
	 -306.7056, -305.577, -304.4483, -303.3195, -302.1906, -301.0616, -299.9324, -298.8031, -297.6737, -296.5442,
	 -295.4146, -294.2848, -293.1549, -292.0249, -290.8948, -289.7645, -288.6342, -287.5037, -286.3731, -285.2424,
	 -284.1116, -282.9806, -281.8496, -280.7184, -279.5871, -278.4557, -277.3242, -276.1926, -275.0609, -273.929,
	 -272.7971, -271.665, -270.5328, -269.4005, -268.2681, -267.1356, -266.003, -264.8703, -263.7374, -262.6045,
	 -261.4715, -260.3383, -259.205, -258.0717, -256.9382, -255.8046, -254.6709, -253.5372, -252.4033, -251.2693,
	 -250.1352, -249.001, -247.8667, -246.7323, -245.5978, -244.4632, -243.3285, -242.1937, -241.0588, -239.9238,
	 -238.7887, -237.6535, -236.5182, -235.3829, -234.2474, -233.1118, -231.9761, -230.8404, -229.7045, -228.5686,
	 -227.4325, -226.2964, -225.1601, -224.0238, -222.8874, -221.7509, -220.6143, -219.4776, -218.3408, -217.2039,
	 -216.067, -214.9299, -213.7928, -212.6556, -211.5183, -210.3809, -209.2434, -208.1058, -206.9682, -205.8304,
	 -204.6926, -203.5547, -202.4167, -201.2786, -200.1405, -199.0022, -197.8639, -196.7255, -195.587, -194.4485,
	 -193.3098, -192.1711, -191.0323, -189.8934, -188.7545, -187.6154, -186.4763, -185.3371, -184.1979, -183.0585,
	 -181.9191, -180.7796, -179.6401, -178.5004, -177.3607, -176.2209, -175.0811, -173.9411, -172.8011, -171.6611,
	 -170.5209, -169.3807, -168.2404, -167.1001, -165.9597, -164.8192, -163.6786, -162.538, -161.3973, -160.2565,
	 -159.1157, -157.9748, -156.8339, -155.6929, -154.5518, -153.4106, -152.2694, -151.1281, -149.9868, -148.8454,
	 -147.7039, -146.5624, -145.4208, -144.2792, -143.1375, -141.9958, -140.8539, -139.7121, -138.5701, -137.4281,
	 -136.2861, -135.144, -134.0018, -132.8596, -131.7173, -130.575, -129.4326, -128.2902, -127.1477, -126.0052,
	 -124.8626, -123.72, -122.5773, -121.4345, -120.2917, -119.1489, -118.006, -116.8631, -115.7201, -114.5771,
	 -113.434, -112.2908, -111.1477, -110.0044, -108.8612, -107.7179, -106.5745, -105.4311, -104.2877, -103.1442,
	 -102.0006, -100.8571, -99.7135, -98.5698, -97.4261, -96.2824, -95.1386, -93.9948, -92.8509, -91.707,
	 -90.5631, -89.4191, -88.2751, -87.1311, -85.987, -84.8429, -83.6987, -82.5546, -81.4103, -80.2661,
	 -79.1218, -77.9775, -76.8331, -75.6888, -74.5443, -73.3999, -72.2554, -71.1109, -69.9664, -68.8218,
	 -67.6772, -66.5326, -65.388, -64.2433, -63.0986, -61.9539, -60.8091, -59.6643, -58.5195, -57.3747,
	 -56.2299, -55.085, -53.9401, -52.7952, -51.6502, -50.5053, -49.3603, -48.2153, -47.0703, -45.9252,
	 -44.7802, -43.6351, -42.49, -41.3449, -40.1997, -39.0546, -37.9094, -36.7642, -35.619, -34.4738,
	 -33.3286, -32.1834, -31.0381, -29.8928, -28.7476, -27.6023, -26.457, -25.3117, -24.1663, -23.021,
	 -21.8757, -20.7303, -19.5849, -18.4396, -17.2942, -16.1488, -15.0034, -13.858, -12.7126, -11.5672,
	 -10.4218, -9.2764, -8.131, -6.9855, -5.8401, -4.6947, -3.5493, -2.4038, -1.2584, -0.11296,
	 1.0325, 2.1779, 3.3233, 4.4688, 5.6142, 6.7596, 7.9051, 9.0505, 10.1959, 11.3413,
	 12.4867, 13.6321, 14.7775, 15.9229, 17.0683, 18.2137, 19.359, 20.5044, 21.6498, 22.7951,
	 23.9404, 25.0858, 26.2311, 27.3764, 28.5217, 29.667, 30.8122, 31.9575, 33.1027, 34.248,
	 35.3932, 36.5384, 37.6836, 38.8287, 39.9739, 41.119, 42.2641, 43.4092, 44.5543, 45.6994,
	 46.8444, 47.9895, 49.1345, 50.2794, 51.4244, 52.5694, 53.7143, 54.8592, 56.0041, 57.1489,
	 58.2937, 59.4386, 60.5833, 61.7281, 62.8728, 64.0175, 65.1622, 66.3069, 67.4515, 68.5961,
	 69.7406, 70.8852, 72.0297, 73.1742, 74.3186, 75.463, 76.6074, 77.7518, 78.8961, 80.0404,
	 81.1847, 82.3289, 83.4731, 84.6172, 85.7614, 86.9054, 88.0495, 89.1935, 90.3375, 91.4814,
	 92.6253, 93.7692, 94.913, 96.0568, 97.2005, 98.3442, 99.4879, 100.6315, 101.7751, 102.9186,
	 104.0621, 105.2056, 106.349, 107.4924, 108.6357, 109.779, 110.9222, 112.0654, 113.2085, 114.3516,
	 115.4947, 116.6377, 117.7806, 118.9235, 120.0663, 121.2092, 122.3519, 123.4946, 124.6373, 125.7799,
	 126.9224, 128.0649, 129.2073, 130.3497, 131.4921, 132.6343, 133.7766, 134.9187, 136.0608, 137.2029,
	 138.3449, 139.4868, 140.6287, 141.7706, 142.9123, 144.054, 145.1957, 146.3373, 147.4788, 148.6203,
	 149.7617, 150.903, 152.0443, 153.1855, 154.3267, 155.4678, 156.6088, 157.7498, 158.8907, 160.0315,
	 161.1723, 162.313, 163.4537, 164.5942, 165.7347, 166.8752, 168.0155, 169.1558, 170.296, 171.4362,
	 172.5763, 173.7163, 174.8562, 175.9961, 177.1359, 178.2756, 179.4153, 180.5549, 181.6944, 182.8338,
	 183.9732, 185.1124, 186.2516, 187.3908, 188.5298, 189.6688, 190.8077, 191.9465, 193.0852, 194.2239,
	 195.3625, 196.501, 197.6394, 198.7777, 199.916, 201.0542, 202.1922, 203.3303, 204.4682, 205.606,
	 206.7438, 207.8814, 209.019, 210.1565, 211.2939, 212.4313, 213.5685, 214.7057, 215.8427, 216.9797,
	 218.1166, 219.2534, 220.3901, 221.5267, 222.6632, 223.7997, 224.936, 226.0723, 227.2084, 228.3445,
	 229.4805, 230.6164, 231.7521, 232.8878, 234.0234, 235.1589, 236.2943, 237.4296, 238.5648, 239.7,
	 240.835, 241.9699, 243.1047, 244.2394, 245.374, 246.5086, 247.643, 248.7773, 249.9115, 251.0456,
	 252.1796, 253.3135, 254.4473, 255.581, 256.7146, 257.8481, 258.9815, 260.1148, 261.248, 262.381,
	 263.514, 264.6469, 265.7796, 266.9122, 268.0448, 269.1772, 270.3095, 271.4417, 272.5738, 273.7058,
	 274.8376, 275.9694, 277.101, 278.2326, 279.364, 280.4953, 281.6265, 282.7576, 283.8885, 285.0194,
	 286.1501, 287.2807, 288.4112, 289.5416, 290.6719, 291.802, 292.932, 294.062, 295.1917, 296.3214,
	 297.451, 298.5804, 299.7097, 300.8389, 301.968, 303.0969, 304.2257, 305.3544, 306.483, 307.6114,
	 308.7398, 309.868, 310.996, 312.124, 313.2518, 314.3795, 315.5071, 316.6345, 317.7618, 318.889,
	 320.0161, 321.143, 322.2698, 323.3965, 324.523, 325.6494, 326.7757, 327.9018, 329.0279, 330.1537,
	 331.2795, 332.4051, 333.5306, 334.6559, 335.7811, 336.9062, 338.0311, 339.1559, 340.2806, 341.4051,
	 342.5295, 343.6538, 344.7779, 345.9019, 347.0257, 348.1494, 349.273, 350.3964, 351.5197, 352.6428,
	 353.7658, 354.8887, 356.0114, 357.1339, 358.2564, 359.3787, 360.5008, 361.6228, 362.7446, 363.8663,
	 364.9879, 366.1093, 367.2306, 368.3517, 369.4727, 370.5935, 371.7142, 372.8347, 373.9551, 375.0753,
	 376.1954, 377.3153, 378.4351, 379.5547, 380.6742, 381.7935, 382.9127, 384.0317, 385.1505, 386.2692,
	 387.3878, 388.5062, 389.6244, 390.7425, 391.8605, 392.9783, 394.0959, 395.2133, 396.3307, 397.4478,
	 398.5648, 399.6816, 400.7983, 401.9148, 403.0312, 404.1474, 405.2634, 406.3793, 407.495, 408.6106,
	 409.7259, 410.8412, 411.9562, 413.0711, 414.1859, 415.3004, 416.4149, 417.5291, 418.6432, 419.7571,
	 420.8708, 421.9844, 423.0978, 424.2111, 425.3242, 426.4371, 427.5498, 428.6624, 429.7748, 430.887,
	 431.9991, 433.111, 434.2227, 435.3342, 436.4456, 437.5568, 438.6679, 439.7787, 440.8894, 441.9999,
	 443.1103, 444.2204, 445.3304, 446.4402, 447.5499, 448.6593, 449.7686, 450.8777, 451.9867, 453.0954,
	 454.204, 455.3124, 456.4206, 457.5287, 458.6365, 459.7442, 460.8517, 461.959, 463.0662, 464.1731,
	 465.2799, 466.3865, 467.4929, 468.5991, 469.7052, 470.811, 471.9167, 473.0222, 474.1275, 475.2326,
	 476.3376, 477.4423, 478.5469, 479.6513, 480.7554, 481.8595, 482.9633, 484.0669, 485.1703, 486.2736,
	 487.3766, 488.4795, 489.5822, 490.6847, 491.787, 492.8891, 493.991, 495.0927, 496.1942, 497.2956,
	 498.3967, 499.4977, 500.5984, 501.699, 502.7994, 503.8995, 504.9995, 506.0993, 507.1989, 508.2983,
	 509.3975, 510.4965, 511.5953, 512.6939, 513.7923, 514.8905, 515.9885, 517.0863, 518.1839, 519.2813,
	 520.3785, 521.4755, 522.5723, 523.6689, 524.7653, 525.8615, 526.9575, 528.0533, 529.1488, 530.2442,
	 531.3394, 532.4344, 533.5292, 534.6237, 535.7181, 536.8122, 537.9062, 538.9999, 540.0934, 541.1868,
	 542.2799, 543.3728, 544.4655, 545.558, 546.6503, 547.7424, 548.8342, 549.9259, 551.0173, 552.1085,
	 553.1996, 554.2904, 555.381, 556.4714, 557.5615, 558.6515, 559.7412, 560.8308, 561.9201, 563.0092,
	 564.0981, 565.1868, 566.2752, 567.3635, 568.4515, 569.5393, 570.6269, 571.7143, 572.8015, 573.8884,
	 574.9751, 576.0616, 577.1479, 578.234, 579.3198, 580.4055, 581.4909, 582.5761, 583.661, 584.7458,
	 585.8303, 586.9146, 587.9987, 589.0825, 590.1662, 591.2496, 592.3328, 593.4157, 594.4985, 595.581,
	 596.6633, 597.7454, 598.8272, 599.9088, 600.9902, 602.0714, 603.1523, 604.233, 605.3135, 606.3938,
	 607.4738, 608.5536, 609.6332, 610.7125, 611.7916, 612.8705, 613.9491, 615.0276, 616.1058, 617.1837,
	 618.2614, 619.3389, 620.4162, 621.4932, 622.57, 623.6466, 624.7229, 625.799, 626.8749, 627.9505,
	 629.0259, 630.1011, 631.176, 632.2507, 633.3252, 634.3994, 635.4734, 636.5471, 637.6206, 638.6939,
	 639.7669, 640.8397, 641.9123, 642.9846, 644.0567, 645.1285, 646.2001, 647.2715, 648.3426, 649.4135,
	 650.4841, 651.5545, 652.6247, 653.6946, 654.7643, 655.8337, 656.9029, 657.9718, 659.0406, 660.109,
	 661.1772, 662.2452, 663.3129, 664.3804, 665.4477, 666.5146, 667.5814, 668.6479, 669.7142, 670.7802,
	 671.8459, 672.9114, 673.9767, 675.0417, 676.1065, 677.171, 678.2353, 679.2993, 680.3631, 681.4266,
	 682.4899, 683.5529, 684.6157, 685.6782, 686.7405, 687.8025, 688.8643, 689.9258, 690.9871, 692.0481,
	 693.1089, 694.1694, 695.2297, 696.2897, 697.3494, 698.4089, 699.4682, 700.5271, 701.5859, 702.6444,
	 703.7026, 704.7605, 705.8183, 706.8757, 707.9329, 708.9899, 710.0465, 711.103, 712.1591, 713.215,
	 714.2707, 715.3261, 716.3812, 717.4361, 718.4907, 719.5451, 720.5992, 721.653, 722.7066, 723.7599,
	 724.813, 725.8657, 726.9183, 727.9705, 729.0226, 730.0743, 731.1258, 732.177, 733.228, 734.2787,
	 735.3291, 736.3792, 737.4292, 738.4788, 739.5282, 740.5773, 741.6261, 742.6747, 743.723, 744.771,
	 745.8188, 746.8663, 747.9136, 748.9605, 750.0073, 751.0537, 752.0999, 753.1458, 754.1914, 755.2368,
	 756.2819, 757.3267, 758.3713, 759.4156, 760.4596, 761.5033, 762.5468, 763.59, 764.633, 765.6756,
	 766.718, 767.7602, 768.802, 769.8436, 770.8849, 771.9259, 772.9667, 774.0072, 775.0474, 776.0873,
	 777.127, 778.1664, 779.2055, 780.2444, 781.2829, 782.3212, 783.3592, 784.397, 785.4345, 786.4716,
	 787.5086, 788.5452, 789.5816, 790.6176, 791.6534, 792.689, 793.7242, 794.7592, 795.7939, 796.8283,
	 797.8624, 798.8963, 799.9299, 800.9632, 801.9962, 803.0289, 804.0614, 805.0936, 806.1255, 807.1571,
	 808.1884, 809.2195, 810.2502, 811.2807, 812.3109, 813.3409, 814.3705, 815.3999, 816.4289, 817.4577,
	 818.4862, 819.5145, 820.5424, 821.5701, 822.5974, 823.6245, 824.6513, 825.6778, 826.7041, 827.73,
	 828.7557, 829.7811, 830.8062, 831.831, 832.8555, 833.8797, 834.9037, 835.9273, 836.9507, 837.9738,
	 838.9966, 840.0191, 841.0413, 842.0632, 843.0848, 844.1062, 845.1273, 846.148, 847.1685, 848.1887,
	 849.2086, 850.2282, 851.2475, 852.2666, 853.2853, 854.3038, 855.3219, 856.3398, 857.3574, 858.3746,
	 859.3916, 860.4083, 861.4247, 862.4408, 863.4567, 864.4722, 865.4874, 866.5024, 867.517, 868.5314,
	 869.5454, 870.5592, 871.5726, 872.5858, 873.5987, 874.6113, 875.6236, 876.6356, 877.6473, 878.6587,
	 879.6698, 880.6806, 881.6911, 882.7013, 883.7112, 884.7208, 885.7302, 886.7392, 887.7479, 888.7563,
	 889.7645, 890.7723, 891.7798, 892.7871, 893.794, 894.8006, 895.807, 896.813, 897.8188, 898.8242,
	 899.8293, 900.8342, 901.8387, 902.843, 903.8469, 904.8505, 905.8539, 906.8569, 907.8596, 908.8621,
	 909.8642, 910.866, 911.8675, 912.8688, 913.8697, 914.8703, 915.8706, 916.8706, 917.8703, 918.8697,
	 919.8688, 920.8676, 921.8661, 922.8643, 923.8622, 924.8598, 925.8571, 926.854, 927.8507, 928.8471,
	 929.8431, 930.8389, 931.8343, 932.8294, 933.8243, 934.8188, 935.813, 936.8069, 937.8005, 938.7938,
	 939.7868, 940.7795, 941.7719, 942.7639, 943.7557, 944.7472, 945.7383, 946.7291, 947.7197, 948.7099,
	 949.6998, 950.6894, 951.6787, 952.6677, 953.6563, 954.6447, 955.6328, 956.6205, 957.6079, 958.5951,
	 959.5819, 960.5684, 961.5546, 962.5405, 963.526, 964.5113, 965.4962, 966.4809, 967.4652, 968.4492,
	 969.4329, 970.4163, 971.3994, 972.3822, 973.3646, 974.3467, 975.3286, 976.3101, 977.2913, 978.2722,
	 979.2527, 980.233, 981.213, 982.1926, 983.1719, 984.1509, 985.1296, 986.108, 987.086, 988.0638,
	 989.0412, 990.0183, 990.9951, 991.9716, 992.9478, 993.9237, 994.8992, 995.8744, 996.8493, 997.8239,
	 998.7982, 999.7722, 1000.7458, 1001.7191, 1002.6921, 1003.6648, 1004.6372, 1005.6093, 1006.581, 1007.5524,
	 1008.5235, 1009.4943, 1010.4648, 1011.4349, 1012.4048, 1013.3743, 1014.3435, 1015.3124, 1016.2809, 1017.2492,
	 1018.2171, 1019.1847, 1020.152, 1021.1189, 1022.0856, 1023.0519, 1024.0179, 1024.9836, 1025.949, 1026.914,
	 1027.8787, 1028.8431, 1029.8072, 1030.771, 1031.7344, 1032.6976, 1033.6604, 1034.6228, 1035.585, 1036.5468,
	 1037.5083, 1038.4695, 1039.4304, 1040.391, 1041.3512, 1042.3111, 1043.2707, 1044.23, 1045.1889, 1046.1475,
	 1047.1058, 1048.0638, 1049.0214, 1049.9788, 1050.9358, 1051.8924, 1052.8488, 1053.8048, 1054.7605, 1055.7159,
	 1056.671, 1057.6257, 1058.5801, 1059.5342, 1060.488, 1061.4414, 1062.3946, 1063.3474, 1064.2998, 1065.252,
	 1066.2038, 1067.1553, 1068.1065, 1069.0573, 1070.0078, 1070.958, 1071.9079, 1072.8574, 1073.8066, 1074.7555,
	 1075.7041, 1076.6523, 1077.6002, 1078.5478, 1079.4951, 1080.442, 1081.3886, 1082.3349, 1083.2809, 1084.2265,
	 1085.1718, 1086.1168, 1087.0614, 1088.0057, 1088.9497, 1089.8934, 1090.8367, 1091.7797, 1092.7224, 1093.6648,
	 1094.6068, 1095.5485, 1096.4899, 1097.4309, 1098.3716, 1099.312, 1100.2521, 1101.1918, 1102.1312, 1103.0703,
	 1104.009, 1104.9474, 1105.8855, 1106.8233, 1107.7607, 1108.6978, 1109.6346, 1110.571, 1111.5071, 1112.4429,
	 1113.3784, 1114.3135, 1115.2483, 1116.1827, 1117.1169, 1118.0507, 1118.9841, 1119.9173, 1120.8501, 1121.7826,
	 1122.7147, 1123.6465, 1124.578, 1125.5092, 1126.44, 1127.3705, 1128.3007, 1129.2305, 1130.16, 1131.0892,
	 1132.018, 1132.9465, 1133.8747, 1134.8026, 1135.7301, 1136.6573, 1137.5841, 1138.5106, 1139.4368, 1140.3627,
	 1141.2882, 1142.2134, 1143.1383, 1144.0628, 1144.987, 1145.9109, 1146.8344, 1147.7576, 1148.6805, 1149.603,
	 1150.5252, 1151.4471, 1152.3686, 1153.2898, 1154.2107, 1155.1312, 1156.0514, 1156.9713, 1157.8908, 1158.81,
	 1159.7289, 1160.6474, 1161.5656, 1162.4835, 1163.401, 1164.3182, 1165.2351, 1166.1517, 1167.0679, 1167.9837,
	 1168.8993, 1169.8145, 1170.7293, 1171.6439, 1172.5581, 1173.4719, 1174.3854, 1175.2986, 1176.2115, 1177.124,
	 1178.0362, 1178.9481, 1179.8596, 1180.7708, 1181.6816, 1182.5922, 1183.5023, 1184.4122, 1185.3217, 1186.2309,
	 1187.1397, 1188.0482, 1188.9564, 1189.8642, 1190.7717, 1191.6789, 1192.5857, 1193.4922, 1194.3984, 1195.3042,
	 1196.2097, 1197.1149, 1198.0197, 1198.9242, 1199.8283, 1200.7321, 1201.6356, 1202.5388, 1203.4416, 1204.344,
	 1205.2462, 1206.1479, 1207.0494, 1207.9505, 1208.8513, 1209.7518, 1210.6519, 1211.5517, 1212.4511, 1213.3502,
	 1214.249, 1215.1474, 1216.0455, 1216.9433, 1217.8407, 1218.7378, 1219.6345, 1220.5309, 1221.427, 1222.3227,
	 1223.2181, 1224.1132, 1225.0079, 1225.9023, 1226.7964, 1227.6901, 1228.5835, 1229.4765, 1230.3692, 1231.2616,
	 1232.1536, 1233.0453, 1233.9367, 1234.8277, 1235.7184, 1236.6087, 1237.4987, 1238.3884, 1239.2777, 1240.1667,
	 1241.0554, 1241.9437, 1242.8317, 1243.7193, 1244.6066, 1245.4936, 1246.3803, 1247.2665, 1248.1525, 1249.0381,
	 1249.9234, 1250.8083, 1251.6929, 1252.5772, 1253.4611, 1254.3447, 1255.228, 1256.1109, 1256.9935, 1257.8757,
	 1258.7576, 1259.6392, 1260.5204, 1261.4013, 1262.2818, 1263.1621, 1264.0419, 1264.9215, 1265.8007, 1266.6795,
	 1267.558, 1268.4362, 1269.3141, 1270.1916, 1271.0687, 1271.9456, 1272.8221, 1273.6982, 1274.574, 1275.4495,
	 1276.3246, 1277.1994, 1278.0739, 1278.948, 1279.8218, 1280.6952, 1281.5683, 1282.4411, 1283.3135, 1284.1856,
	 1285.0574, 1285.9288, 1286.7999, 1287.6706, 1288.541, 1289.4111, 1290.2808, 1291.1502, 1292.0192, 1292.8879,
	 1293.7563, 1294.6243, 1295.492, 1296.3593, 1297.2263, 1298.093, 1298.9593, 1299.8253, 1300.691, 1301.5563,
	 1302.4213, 1303.2859, 1304.1502, 1305.0142, 1305.8778, 1306.7411, 1307.604, 1308.4666, 1309.3289, 1310.1908,
	 1311.0524, 1311.9137, 1312.7746, 1313.6352, 1314.4954, 1315.3553, 1316.2149, 1317.0741, 1317.933, 1318.7915,
	 1319.6497, 1320.5076, 1321.3651, 1322.2223, 1323.0791, 1323.9356, 1324.7918, 1325.6476, 1326.5031, 1327.3583,
	 1328.2131, 1329.0676, 1329.9217, 1330.7755, 1331.629, 1332.4821, 1333.3349, 1334.1873, 1335.0394, 1335.8912,
	 1336.7426, 1337.5937, 1338.4444, 1339.2948, 1340.1449, 1340.9946, 1341.844, 1342.6931, 1343.5418, 1344.3902,
	 1345.2382, 1346.0859, 1346.9333, 1347.7803, 1348.627, 1349.4734, 1350.3194, 1351.165, 1352.0104, 1352.8554,
	 1353.7, 1354.5443, 1355.3883, 1356.2319, 1357.0752, 1357.9182, 1358.7608, 1359.6031, 1360.4451, 1361.2867,
	 1362.1279, 1362.9689, 1363.8095, 1364.6497, 1365.4896, 1366.3292, 1367.1684, 1368.0073, 1368.8459, 1369.6841,
	 1370.522, 1371.3596, 1372.1968, 1373.0337, 1373.8702, 1374.7064, 1375.5422, 1376.3778, 1377.2129, 1378.0478,
	 1378.8823, 1379.7165, 1380.5503, 1381.3838, 1382.2169, 1383.0498, 1383.8822, 1384.7144, 1385.5462, 1386.3776,
	 1387.2088, 1388.0396, 1388.87, 1389.7001, 1390.5299, 1391.3593, 1392.1884, 1393.0172, 1393.8456, 1394.6737,
	 1395.5015, 1396.3289, 1397.1559, 1397.9827, 1398.8091, 1399.6352, 1400.4609, 1401.2863, 1402.1113, 1402.936,
	 1403.7604, 1404.5844, 1405.4081, 1406.2315, 1407.0545, 1407.8772, 1408.6996, 1409.5216, 1410.3433, 1411.1646,
	 1411.9856, 1412.8063, 1413.6266, 1414.4466, 1415.2663, 1416.0856, 1416.9046, 1417.7232, 1418.5416, 1419.3595,
	 1420.1772, 1420.9945, 1421.8114, 1422.6281, 1423.4444, 1424.2603, 1425.0759, 1425.8912, 1426.7062, 1427.5208,
	 1428.335, 1429.149, 1429.9626, 1430.7759, 1431.5888, 1432.4014, 1433.2136, 1434.0256, 1434.8371, 1435.6484,
	 1436.4593, 1437.2699, 1438.0801, 1438.89, 1439.6996, 1440.5088, 1441.3177, 1442.1263, 1442.9345, 1443.7424,
	 1444.55, 1445.3572, 1446.1641, 1446.9707, 1447.7769, 1448.5828, 1449.3883, 1450.1935, 1450.9984, 1451.8029,
	 1452.6071, 1453.411, 1454.2145, 1455.0177, 1455.8206, 1456.6231, 1457.4253, 1458.2272, 1459.0287, 1459.8299,
	 1460.6308, 1461.4313, 1462.2315, 1463.0313, 1463.8309, 1464.6301, 1465.4289, 1466.2274, 1467.0256, 1467.8235,
	 1468.621, 1469.4182, 1470.215, 1471.0115, 1471.8077, 1472.6035, 1473.3991, 1474.1942, 1474.9891, 1475.7836,
	 1476.5778, 1477.3716, 1478.1651, 1478.9583, 1479.7511, 1480.5437, 1481.3358, 1482.1277, 1482.9192, 1483.7104,
	 1484.5012, 1485.2917, 1486.0819, 1486.8718, 1487.6613, 1488.4505, 1489.2393, 1490.0278, 1490.816, 1491.6039,
	 1492.3914, 1493.1786, 1493.9654, 1494.7519, 1495.5381, 1496.324, 1497.1095, 1497.8947, 1498.6796, 1499.4641,
	 1500.2483, 1501.0321, 1501.8157, 1502.5989, 1503.3817, 1504.1643, 1504.9465, 1505.7284, 1506.5099, 1507.2911,
	 1508.072, 1508.8526, 1509.6328, 1510.4127, 1511.1922, 1511.9714, 1512.7503, 1513.5289, 1514.3071, 1515.085,
	 1515.8626, 1516.6398, 1517.4168, 1518.1933, 1518.9696, 1519.7455, 1520.5211, 1521.2963, 1522.0713, 1522.8459,
	 1523.6201, 1524.3941, 1525.1677, 1525.941, 1526.7139, 1527.4865, 1528.2588, 1529.0308, 1529.8024, 1530.5737,
	 1531.3447, 1532.1153, 1532.8856, 1533.6556, 1534.4253, 1535.1946, 1535.9636, 1536.7322, 1537.5006, 1538.2686,
	 1539.0363, 1539.8036, 1540.5706, 1541.3373, 1542.1037, 1542.8697, 1543.6354, 1544.4008, 1545.1659, 1545.9306,
	 1546.695, 1547.4591, 1548.2228, 1548.9862, 1549.7493, 1550.5121, 1551.2745, 1552.0366, 1552.7984, 1553.5598,
	 1554.3209, 1555.0817, 1555.8422, 1556.6023, 1557.3621, 1558.1216, 1558.8808, 1559.6396, 1560.3981, 1561.1563,
	 1561.9141, 1562.6717, 1563.4289, 1564.1857, 1564.9423, 1565.6985, 1566.4544, 1567.21, 1567.9652, 1568.7201,
	 1569.4747, 1570.229, 1570.9829, 1571.7365, 1572.4898, 1573.2427, 1573.9954, 1574.7477, 1575.4997, 1576.2513,
	 1577.0027, 1577.7537, 1578.5044, 1579.2547, 1580.0047, 1580.7545, 1581.5038, 1582.2529, 1583.0016, 1583.75,
	 1584.4981, 1585.2459, 1585.9933, 1586.7404, 1587.4872, 1588.2337, 1588.9798, 1589.7257, 1590.4712, 1591.2163,
	 1591.9612, 1592.7057, 1593.4499, 1594.1938, 1594.9373, 1595.6806, 1596.4235, 1597.1661, 1597.9083, 1598.6503,
	 1599.3919, 1600.1332, 1600.8741, 1601.6148, 1602.3551, 1603.0951, 1603.8348, 1604.5742, 1605.3132, 1606.0519,
	 1606.7903, 1607.5284, 1608.2661, 1609.0035, 1609.7407, 1610.4774, 1611.2139, 1611.95, 1612.6859, 1613.4214,
	 1614.1565, 1614.8914, 1615.6259, 1616.3601, 1617.094, 1617.8276, 1618.5609, 1619.2938, 1620.0264, 1620.7587,
	 1621.4907, 1622.2223, 1622.9537, 1623.6847, 1624.4154, 1625.1457, 1625.8758, 1626.6055, 1627.3349, 1628.064,
	 1628.7928, 1629.5213, 1630.2494, 1630.9772, 1631.7047, 1632.4319, 1633.1588, 1633.8853, 1634.6115, 1635.3374,
	 1636.063, 1636.7883, 1637.5132, 1638.2379, 1638.9622, 1639.6862, 1640.4099, 1641.1332, 1641.8563, 1642.579,
	 1643.3014, 1644.0235, 1644.7452, 1645.4667, 1646.1878, 1646.9087, 1647.6292, 1648.3493, 1649.0692, 1649.7888,
	 1650.508, 1651.2269, 1651.9455, 1652.6638, 1653.3818, 1654.0994, 1654.8168, 1655.5338, 1656.2505, 1656.9669,
	 1657.683, 1658.3987, 1659.1142, 1659.8293, 1660.5441, 1661.2586, 1661.9728, 1662.6866, 1663.4002, 1664.1134,
	 1664.8263, 1665.539, 1666.2512, 1666.9632, 1667.6749, 1668.3862, 1669.0973, 1669.808, 1670.5184, 1671.2285,
	 1671.9383, 1672.6477, 1673.3569, 1674.0657, 1674.7742, 1675.4824, 1676.1903, 1676.8979, 1677.6052, 1678.3122,
	 1679.0188, 1679.7251, 1680.4312, 1681.1369, 1681.8423, 1682.5473, 1683.2521, 1683.9566, 1684.6607, 1685.3645,
	 1686.0681, 1686.7713, 1687.4742, 1688.1768, 1688.879, 1689.581, 1690.2826, 1690.984, 1691.685, 1692.3857,
	 1693.0861, 1693.7862, 1694.486, 1695.1855, 1695.8846, 1696.5835, 1697.282, 1697.9803, 1698.6782, 1699.3758,
	 1700.0731, 1700.7701, 1701.4668, 1702.1632, 1702.8592, 1703.555, 1704.2504, 1704.9456, 1705.6404, 1706.3349,
	 1707.0291, 1707.723, 1708.4166, 1709.1099, 1709.8029, 1710.4955, 1711.1879, 1711.8799, 1712.5717, 1713.2631,
	 1713.9542, 1714.645, 1715.3355, 1716.0257, 1716.7156, 1717.4052, 1718.0945, 1718.7835, 1719.4721, 1720.1605,
	 1720.8485, 1721.5363, 1722.2237, 1722.9108, 1723.5977, 1724.2842, 1724.9704, 1725.6563, 1726.3419, 1727.0272,
	 1727.7122, 1728.3968, 1729.0812, 1729.7653, 1730.449, 1731.1325, 1731.8157, 1732.4985, 1733.181, 1733.8633,
	 1734.5452, 1735.2268, 1735.9082, 1736.5892, 1737.2699, 1737.9503, 1738.6304, 1739.3102, 1739.9897, 1740.6689,
	 1741.3478, 1742.0264, 1742.7047, 1743.3826, 1744.0603, 1744.7377, 1745.4147, 1746.0915, 1746.768, 1747.4441,
	 1748.12, 1748.7955, 1749.4708, 1750.1457, 1750.8204, 1751.4947, 1752.1688, 1752.8425, 1753.5159, 1754.1891,
	 1754.8619, 1755.5344, 1756.2067, 1756.8786, 1757.5502, 1758.2216, 1758.8926, 1759.5633, 1760.2337, 1760.9038,
	 1761.5737, 1762.2432, 1762.9124, 1763.5813, 1764.25, 1764.9183, 1765.5863, 1766.254, 1766.9214, 1767.5886,
	 1768.2554, 1768.9219, 1769.5881, 1770.254, 1770.9197, 1771.585, 1772.25, 1772.9147, 1773.5792, 1774.2433,
	 1774.9071, 1775.5707, 1776.2339, 1776.8968, 1777.5595, 1778.2218, 1778.8839, 1779.5456, 1780.2071, 1780.8682,
	 1781.5291, 1782.1896, 1782.8499, 1783.5098, 1784.1695, 1784.8289, 1785.4879, 1786.1467, 1786.8052, 1787.4634,
	 1788.1213, 1788.7788, 1789.4361, 1790.0931, 1790.7498, 1791.4062, 1792.0623, 1792.7182, 1793.3737, 1794.0289,
	 1794.6838, 1795.3385, 1795.9928, 1796.6468, 1797.3006, 1797.954, 1798.6072, 1799.2601, 1799.9126, 1800.5649,
	 1801.2169, 1801.8686, 1802.52, 1803.1711, 1803.8219, 1804.4724, 1805.1226, 1805.7725, 1806.4222, 1807.0715,
	 1807.7205, 1808.3693, 1809.0178, 1809.6659, 1810.3138, 1810.9614, 1811.6087, 1812.2557, 1812.9024, 1813.5488,
	 1814.1949, 1814.8407, 1815.4863, 1816.1315, 1816.7765, 1817.4212, 1818.0655, 1818.7096, 1819.3534, 1819.9969,
	 1820.6401, 1821.283, 1821.9257, 1822.568, 1823.21, 1823.8518, 1824.4933, 1825.1345, 1825.7753, 1826.4159,
	 1827.0562, 1827.6963, 1828.336, 1828.9754, 1829.6146, 1830.2535, 1830.892, 1831.5303, 1832.1683, 1832.806,
	 1833.4434, 1834.0806, 1834.7174, 1835.354, 1835.9902, 1836.6262, 1837.2619, 1837.8973, 1838.5324, 1839.1672,
	 1839.8018, 1840.436, 1841.07, 1841.7037, 1842.3371, 1842.9702, 1843.603, 1844.2355, 1844.8678, 1845.4997,
	 1846.1314, 1846.7628, 1847.3939, 1848.0247, 1848.6552, 1849.2855, 1849.9155, 1850.5451, 1851.1745, 1851.8036,
	 1852.4324, 1853.061, 1853.6892, 1854.3172, 1854.9449, 1855.5723, 1856.1994, 1856.8262, 1857.4527, 1858.079,
	 1858.705, 1859.3307, 1859.9561, 1860.5812, 1861.206, 1861.8306, 1862.4549, 1863.0788, 1863.7026, 1864.326,
	 1864.9491, 1865.572, 1866.1946, 1866.8168, 1867.4389, 1868.0606, 1868.682, 1869.3032, 1869.9241, 1870.5447,
	 1871.165, 1871.785, 1872.4048, 1873.0243, 1873.6435, 1874.2624, 1874.881, 1875.4994, 1876.1175, 1876.7352,
	 1877.3528, 1877.97, 1878.5869, 1879.2036, 1879.82, 1880.4361, 1881.0519, 1881.6675, 1882.2828, 1882.8978,
	 1883.5125, 1884.1269, 1884.7411, 1885.3549, 1885.9685, 1886.5819, 1887.1949, 1887.8077, 1888.4201, 1889.0324,
	 1889.6443, 1890.2559, 1890.8673, 1891.4784, 1892.0892, 1892.6998, 1893.31, 1893.92, 1894.5297, 1895.1391,
	 1895.7483, 1896.3572, 1896.9658, 1897.5741, 1898.1821, 1898.7899, 1899.3974, 1900.0046, 1900.6116, 1901.2182,
	 1901.8246, 1902.4307, 1903.0366, 1903.6421, 1904.2474, 1904.8525, 1905.4572, 1906.0617, 1906.6658, 1907.2698,
	 1907.8734, 1908.4768, 1909.0799, 1909.6827, 1910.2852, 1910.8875, 1911.4895, 1912.0912, 1912.6927, 1913.2938,
	 1913.8947, 1914.4954, 1915.0957, 1915.6958, 1916.2956, 1916.8951, 1917.4944, 1918.0934, 1918.6921, 1919.2906,
	 1919.8887, 1920.4866, 1921.0843, 1921.6816, 1922.2787, 1922.8755, 1923.4721, 1924.0683, 1924.6643, 1925.2601,
	 1925.8555, 1926.4507, 1927.0456, 1927.6403, 1928.2347, 1928.8288, 1929.4226, 1930.0162, 1930.6095, 1931.2025,
	 1931.7952, 1932.3877, 1932.9799, 1933.5719, 1934.1636, 1934.755, 1935.3461, 1935.937, 1936.5276, 1937.1179,
	 1937.708, 1938.2978, 1938.8873, 1939.4766, 1940.0655, 1940.6543, 1941.2427, 1941.8309, 1942.4188, 1943.0065,
	 1943.5939, 1944.181, 1944.7678, 1945.3544, 1945.9407, 1946.5268, 1947.1126, 1947.6981, 1948.2833, 1948.8683,
	 1949.453, 1950.0375, 1950.6216, 1951.2056, 1951.7892, 1952.3726, 1952.9557, 1953.5386, 1954.1212, 1954.7035,
	 1955.2855, 1955.8673, 1956.4489, 1957.0301, 1957.6111, 1958.1919, 1958.7723, 1959.3525, 1959.9325, 1960.5122,
	 1961.0916, 1961.6707, 1962.2496, 1962.8282, 1963.4066, 1963.9847, 1964.5625, 1965.1401, 1965.7174, 1966.2945,
	 1966.8712, 1967.4478, 1968.024, 1968.6, 1969.1757, 1969.7512, 1970.3264, 1970.9014, 1971.4761, 1972.0505,
	 1972.6246, 1973.1985, 1973.7722, 1974.3456, 1974.9187, 1975.4915, 1976.0641, 1976.6365, 1977.2085, 1977.7804,
	 1978.3519, 1978.9232, 1979.4942, 1980.065, 1980.6355, 1981.2058, 1981.7758, 1982.3455, 1982.915, 1983.4842,
	 1984.0531, 1984.6218, 1985.1903, 1985.7585, 1986.3264, 1986.894, 1987.4614, 1988.0286, 1988.5955, 1989.1621,
	 1989.7285, 1990.2946, 1990.8605, 1991.426, 1991.9914, 1992.5565, 1993.1213, 1993.6859, 1994.2502, 1994.8142,
	 1995.378, 1995.9416, 1996.5049, 1997.0679, 1997.6307, 1998.1932, 1998.7554, 1999.3174, 1999.8792, 2000.4407,
	 2001.0019, 2001.5629, 2002.1236, 2002.6841, 2003.2443, 2003.8043, 2004.364, 2004.9234, 2005.4826, 2006.0416,
	 2006.6003, 2007.1587, 2007.7169, 2008.2748, 2008.8325, 2009.3899, 2009.947, 2010.504, 2011.0606, 2011.617,
	 2012.1732, 2012.7291, 2013.2847, 2013.8401, 2014.3952, 2014.9501, 2015.5048, 2016.0591, 2016.6133, 2017.1671,
	 2017.7208, 2018.2741, 2018.8273, 2019.3801, 2019.9327, 2020.4851, 2021.0372, 2021.5891, 2022.1407, 2022.6921,
	 2023.2432, 2023.794, 2024.3446, 2024.895, 2025.4451, 2025.995, 2026.5446, 2027.0939, 2027.643, 2028.1919,
	 2028.7405, 2029.2889, 2029.837, 2030.3848, 2030.9325, 2031.4798, 2032.0269, 2032.5738, 2033.1204, 2033.6668,
	 2034.2129, 2034.7588, 2035.3044, 2035.8498, 2036.3949, 2036.9398, 2037.4844, 2038.0288, 2038.5729, 2039.1168,
	 2039.6604, 2040.2038, 2040.747, 2041.2899, 2041.8325, 2042.3749, 2042.9171, 2043.459, 2044.0007, 2044.5421,
	 2045.0833, 2045.6242, 2046.1649, 2046.7053, 2047.2455, 2047.7854, 2048.3251, 2048.8646, 2049.4038, 2049.9428,
	 2050.4815, 2051.02, 2051.5582, 2052.0962, 2052.6339, 2053.1714, 2053.7087, 2054.2457, 2054.7824, 2055.319,
	 2055.8552, 2056.3913, 2056.9271, 2057.4626, 2057.9979, 2058.533, 2059.0678, 2059.6023, 2060.1367, 2060.6708,
	 2061.2046, 2061.7382, 2062.2716, 2062.8047, 2063.3376, 2063.8702, 2064.4026, 2064.9347, 2065.4666, 2065.9983,
	 2066.5297, 2067.0609, 2067.5919, 2068.1226, 2068.653, 2069.1832, 2069.7132, 2070.243, 2070.7725, 2071.3017,
	 2071.8307, 2072.3595, 2072.888, 2073.4163, 2073.9444, 2074.4722, 2074.9998, 2075.5271, 2076.0542, 2076.5811,
	 2077.1077, 2077.6341, 2078.1602, 2078.6861, 2079.2118, 2079.7372, 2080.2624, 2080.7874, 2081.3121, 2081.8366,
	 2082.3608, 2082.8848, 2083.4085, 2083.9321, 2084.4554, 2084.9784, 2085.5012, 2086.0238, 2086.5461, 2087.0682,
	 2087.5901, 2088.1117, 2088.6331, 2089.1543, 2089.6752, 2090.1959, 2090.7163, 2091.2365, 2091.7565, 2092.2762,
	 2092.7957, 2093.315, 2093.834, 2094.3528, 2094.8714, 2095.3897, 2095.9078, 2096.4257, 2096.9433, 2097.4607,
	 2097.9778, 2098.4947, 2099.0114, 2099.5279, 2100.0441, 2100.5601, 2101.0758, 2101.5913, 2102.1066, 2102.6216,
	 2103.1365, 2103.651, 2104.1654, 2104.6795, 2105.1934, 2105.707, 2106.2205, 2106.7336, 2107.2466, 2107.7593,
	 2108.2718, 2108.7841, 2109.2961, 2109.8079, 2110.3194, 2110.8308, 2111.3419, 2111.8527, 2112.3634, 2112.8738,
	 2113.3839, 2113.8939, 2114.4036, 2114.9131, 2115.4223, 2115.9313, 2116.4401, 2116.9487, 2117.457, 2117.9651,
	 2118.473, 2118.9806, 2119.488, 2119.9952, 2120.5022, 2121.0089, 2121.5154, 2122.0216, 2122.5277, 2123.0335,
	 2123.539, 2124.0444, 2124.5495, 2125.0544, 2125.5591, 2126.0635, 2126.5677, 2127.0717, 2127.5754, 2128.079,
	 2128.5823, 2129.0853, 2129.5882, 2130.0908, 2130.5932, 2131.0953, 2131.5973, 2132.099, 2132.6004, 2133.1017,
	 2133.6027, 2134.1035, 2134.6041, 2135.1044, 2135.6046, 2136.1045, 2136.6041, 2137.1036, 2137.6028, 2138.1018,
	 2138.6006, 2139.0991, 2139.5974, 2140.0955, 2140.5934, 2141.091, 2141.5884, 2142.0856, 2142.5826, 2143.0794,
	 2143.5759, 2144.0722, 2144.5682, 2145.0641, 2145.5597, 2146.0551, 2146.5503, 2147.0453, 2147.54, 2148.0345,
	 2148.5288, 2149.0229, 2149.5167, 2150.0103, 2150.5037, 2150.9969, 2151.4898, 2151.9826, 2152.4751, 2152.9673,
	 2153.4594, 2153.9513, 2154.4429, 2154.9343, 2155.4254, 2155.9164, 2156.4071, 2156.8976, 2157.3879, 2157.878,
	 2158.3679, 2158.8575, 2159.3469, 2159.8361, 2160.325, 2160.8138, 2161.3023, 2161.7906, 2162.2787, 2162.7666,
	 2163.2542, 2163.7417, 2164.2289, 2164.7159, 2165.2026, 2165.6892, 2166.1755, 2166.6616, 2167.1475, 2167.6332,
	 2168.1187, 2168.6039, 2169.0889, 2169.5737, 2170.0583, 2170.5427, 2171.0268, 2171.5107, 2171.9945, 2172.478,
	 2172.9612, 2173.4443, 2173.9271, 2174.4098, 2174.8922, 2175.3744, 2175.8563, 2176.3381, 2176.8196, 2177.301,
	 2177.7821, 2178.263, 2178.7436, 2179.2241, 2179.7044, 2180.1844, 2180.6642, 2181.1438, 2181.6232, 2182.1023,
	 2182.5813, 2183.06, 2183.5386, 2184.0169, 2184.495, 2184.9728, 2185.4505, 2185.928, 2186.4052, 2186.8822,
	 2187.359, 2187.8356, 2188.312, 2188.7882, 2189.2641, 2189.7398, 2190.2154, 2190.6907, 2191.1658, 2191.6407,
	 2192.1153, 2192.5898, 2193.064, 2193.5381, 2194.0119, 2194.4855, 2194.9589, 2195.4321, 2195.905, 2196.3778,
	 2196.8503, 2197.3227, 2197.7948, 2198.2667, 2198.7384, 2199.2099, 2199.6812, 2200.1523, 2200.6231, 2201.0938,
	 2201.5642, 2202.0344, 2202.5044, 2202.9742, 2203.4438, 2203.9132, 2204.3824, 2204.8513, 2205.3201, 2205.7886,
	 2206.257, 2206.7251, 2207.193, 2207.6607, 2208.1282, 2208.5955, 2209.0625, 2209.5294, 2209.9961, 2210.4625,
	 2210.9288, 2211.3948, 2211.8606, 2212.3262, 2212.7916, 2213.2568, 2213.7218, 2214.1866, 2214.6512, 2215.1155,
	 2215.5797, 2216.0436, 2216.5074, 2216.9709, 2217.4343, 2217.8974, 2218.3603, 2218.823, 2219.2855, 2219.7478,
	 2220.2099, 2220.6718, 2221.1335, 2221.5949, 2222.0562, 2222.5172, 2222.9781, 2223.4387, 2223.8992, 2224.3594,
	 2224.8194, 2225.2793, 2225.7389, 2226.1983, 2226.6575, 2227.1165, 2227.5753, 2228.0339, 2228.4923, 2228.9505,
	 2229.4085, 2229.8662, 2230.3238, 2230.7812, 2231.2384, 2231.6953, 2232.1521, 2232.6086, 2233.065, 2233.5247};

//GLOBALISAK
//Sharp ADC
volatile bool SHARP_FRONT_valid=false;
uint16_t SHARP_FRONT_raw =0;
int32_t SHARP_FRONT_filtered=0;
int32_t SHARP_FRONT_array[20]={0,0,0,0,0,0,0,0,0,0,0,0,0,0,0,0,0,0,0,0};

//LABRANGATO
volatile uint32_t actualmotorinput=0;
volatile uint32_t previousmotorinput=0;
bool stop_deadman = false;

//Motor
uint32_t motorpulsePWM=0;
bool stop = false;
bool stop_cel = false;

//Utemezo
volatile uint32_t timestamp;
volatile bool tick=false;

//Encoder
volatile int32_t actualencoderval=0;
int32_t encoder_aktualis=0;
int32_t encoder_elozo=0;
int32_t encoder_diff=0;
int32_t velocity;
HAL_TIM_StateTypeDef encoder_state;
int32_t encoder_diff_WMA=0;
int32_t encoder_diff_array[4]={0,0,0,0};

//Vonalszenzor UART
volatile bool vonalszenzor_uzenetjott=false;
uint8_t uzenetarray[5]={0,0,0,0,0};
uint16_t pozicio_elso=1600;
uint16_t pozicio_masodik=1200;
uint8_t vonaltipus=EGYVONAL;
int16_t orientacio=0;
uint32_t szervoPWM;
uint8_t vonalminta=SIMA_VEZETOVONAL;
uint8_t lassito_szakaszok_szama=0;

//Safety car
bool safetycar_aktiv=true;
char string[20];
bool stop_safetycar=false;
bool elso_gyorsito=true;
uint8_t kor=ELSOKOR;

int32_t mmpersec_sebesseg=0;
bool fekeztunk_mar=true;
bool eltolt_gyorsulas=false;
uint32_t start_tick=0;
uint32_t start_tick_lassito=0;
uint8_t allapotteres_szabalyozo=NORMAL;

/* USER CODE END PV */

void SystemClock_Config(void);
void Error_Handler(void);

/* USER CODE BEGIN PFP */
/* Private function prototypes -----------------------------------------------*/
void Motorkezeles();
void Vonalszenzorkezeles_uartfogadas();
void allapotteres_szabalyozo_kanyar_kijarat(uint16_t* pozicio, int16_t* orientacio, int32_t* sebesseg, uint32_t* PWMeredmeny);
void allapotteres_szabalyozo_default(uint16_t* pozicio, int16_t* orientacio, int32_t* sebesseg, uint32_t* PWMeredmeny);
void WMAfilter(int32_t* filteredval, int32_t* newelement, int32_t* array, uint32_t filter_depth);
void Encoder_beolvasas();
void Safety_car_old();
void Safety_car_P();
void sebessegszabalyozo(int32_t mmpersec);
void fekezo_sebessegszabalyozo(int32_t mmpersec);
void vonalminta_felismeres();
void lassitora_mitcsinalunk();
void gyorsitora_mitcsinalunk();

/* USER CODE END PFP */

/* USER CODE BEGIN 0 */

void HAL_ADC_ConvCpltCallback(ADC_HandleTypeDef* hadc)
{
	if (hadc->Instance == ADC1)
		SHARP_FRONT_valid = true; //eleg egyet beolvasni
}
void HAL_TIM_IC_CaptureCallback(TIM_HandleTypeDef* htim)
{
	if (htim->Instance == TIM4)
	{
		previousmotorinput = actualmotorinput;
		actualmotorinput = HAL_TIM_ReadCapturedValue(&htim4,TIM_CHANNEL_1);
		__HAL_TIM_SET_COUNTER(&htim4,0);
	}
}
void HAL_TIM_PeriodElapsedCallback(TIM_HandleTypeDef *htim)
{
	if(htim->Instance == TIM7)
	{
		timestamp++;
		actualencoderval=HAL_TIM_ReadCapturedValue(&htim2, TIM_CHANNEL_1);
		tick = true;
	}
}

void HAL_UART_RxCpltCallback(UART_HandleTypeDef *huart)
{
	if (huart->Instance ==USART1)
	{
		vonalszenzor_uzenetjott=true;
	}
}
//Uart neha csinal random ORE-t
void HAL_UART_ErrorCallback(UART_HandleTypeDef *huart)
{
	if (huart->Instance ==USART1)
	{
	    if (huart->ErrorCode == HAL_UART_ERROR_ORE)//Néha random overrun hiba, ekkor kinullázuk
	    {
	            // remove the error condition
	            huart->ErrorCode = HAL_UART_ERROR_NONE;
	            // set the correct state, so that the UART_RX_IT works correctly
	            huart->gState = HAL_UART_STATE_BUSY_RX;
	    }
	}
}

/* USER CODE END 0 */

int main(void)

{

  /* MCU Configuration----------------------------------------------------------*/

  /* Reset of all peripherals, Initializes the Flash interface and the Systick. */
  HAL_Init();

  /* Configure the system clock */
  SystemClock_Config();

  /* Initialize all configured peripherals */
  MX_GPIO_Init();
  MX_DMA_Init();
  MX_ADC1_Init();
  MX_SPI1_Init();
  MX_TIM1_Init();
  MX_TIM2_Init();
  MX_TIM8_Init();
  MX_UART4_Init();
  MX_UART5_Init();
  MX_USART1_UART_Init();
  MX_TIM6_Init();
  MX_USART2_UART_Init();
  MX_TIM4_Init();
  MX_TIM7_Init();

  /* USER CODE BEGIN 2 */

  HAL_TIMEx_PWMN_Start(&htim1, TIM_CHANNEL_2);
  HAL_TIMEx_PWMN_Start(&htim8, TIM_CHANNEL_3);
  __HAL_TIM_SET_COMPARE(&htim8, TIM_CHANNEL_3, 6932);
  HAL_TIM_Base_Start_IT(&htim7);
  HAL_TIM_IC_Start_IT(&htim4,TIM_CHANNEL_1);
  HAL_TIM_Encoder_Start(&htim2, TIM_CHANNEL_1);

  //Vonalszenzortol uzenetek fogadasa
  HAL_UART_Receive_DMA(&huart1, uzenetarray, 5);

  //Alap sebesseg megadasa  D
 // motorpulsePWM = 7300;
  mmpersec_sebesseg=700;

  /* USER CODE END 2 */

  /* Infinite loop */
  while (1)
  {

  /* USER CODE BEGIN 3 */

	  if(lassito_szakaszok_szama==18)
		  stop_cel=true;
	  if(lassito_szakaszok_szama > 5 && lassito_szakaszok_szama < 10)
		  kor=MASODIKKOR;
	  if(lassito_szakaszok_szama > 9 )
		  kor=HARMADIKKOR;

	  if(vonalszenzor_uzenetjott==true) //3ms-onkent kapunk uzenetet
	  {
		  Vonalszenzorkezeles_uartfogadas();
	  }
	  Motorkezeles();

	  vonalminta_felismeres();

	  if(tick) //10ms
	  {
		  HAL_ADC_Start_DMA(&hadc1, (uint32_t*) &SHARP_FRONT_raw, 1); //SHARP front adc elinditasa

		  Encoder_beolvasas();

		  while(!SHARP_FRONT_valid);//Ha mar letelt az ad konverzio ideje, akkor szurjuk a kapott AD erteket
		  WMAfilter(&SHARP_FRONT_filtered,(int32_t*)&(SHARP_FRONT_raw),SHARP_FRONT_array,20);
		  if(safetycar_aktiv)
		  {
			  Safety_car_P();
		  }

		  if(eltolt_gyorsulas)
		  {
			  	safetycar_aktiv=false;
				if(start_tick==0)
					start_tick=timestamp;

				if(timestamp-start_tick > 60)
				{
					mmpersec_sebesseg=3050;
					if(MASODIKKOR)
						mmpersec_sebesseg=3750;
					if(HARMADIKKOR)
						mmpersec_sebesseg=3900;
					start_tick=0;
					eltolt_gyorsulas=false;
				}
		  }

		  if(fekeztunk_mar==false )
		  {
				if(start_tick_lassito==0)
					start_tick_lassito=timestamp;

				if(timestamp-start_tick_lassito > 85) //50
				{
					mmpersec_sebesseg=820; //muszaj hogy levegyuk, hogy bevegye a kanyart
					if(MASODIKKOR)
						mmpersec_sebesseg=950;
					if(HARMADIKKOR)
						mmpersec_sebesseg=1100;
					start_tick_lassito=0;
					fekeztunk_mar=true;
				}
				else
				{
					  if (encoder_diff > 3)
						  motorpulsePWM=4000;
					  else
						  motorpulsePWM=6932;
				}
		  }
		  else
		  {
			  sebessegszabalyozo(mmpersec_sebesseg);
		  }

		  tick=false;
	  }
  }
  /* USER CODE END 3 */

}

/** System Clock Configuration
*/
void SystemClock_Config(void)
{

  RCC_OscInitTypeDef RCC_OscInitStruct;
  RCC_ClkInitTypeDef RCC_ClkInitStruct;

    /**Configure the main internal regulator output voltage
    */
  __HAL_RCC_PWR_CLK_ENABLE();

  __HAL_PWR_VOLTAGESCALING_CONFIG(PWR_REGULATOR_VOLTAGE_SCALE1);

    /**Initializes the CPU, AHB and APB busses clocks
    */
  RCC_OscInitStruct.OscillatorType = RCC_OSCILLATORTYPE_HSE;
  RCC_OscInitStruct.HSEState = RCC_HSE_ON;
  RCC_OscInitStruct.PLL.PLLState = RCC_PLL_ON;
  RCC_OscInitStruct.PLL.PLLSource = RCC_PLLSOURCE_HSE;
  RCC_OscInitStruct.PLL.PLLM = 4;
  RCC_OscInitStruct.PLL.PLLN = 180;
  RCC_OscInitStruct.PLL.PLLP = RCC_PLLP_DIV2;
  RCC_OscInitStruct.PLL.PLLQ = 2;
  RCC_OscInitStruct.PLL.PLLR = 2;
  if (HAL_RCC_OscConfig(&RCC_OscInitStruct) != HAL_OK)
  {
    Error_Handler();
  }

    /**Activate the Over-Drive mode
    */
  if (HAL_PWREx_EnableOverDrive() != HAL_OK)
  {
    Error_Handler();
  }

    /**Initializes the CPU, AHB and APB busses clocks
    */
  RCC_ClkInitStruct.ClockType = RCC_CLOCKTYPE_HCLK|RCC_CLOCKTYPE_SYSCLK
                              |RCC_CLOCKTYPE_PCLK1|RCC_CLOCKTYPE_PCLK2;
  RCC_ClkInitStruct.SYSCLKSource = RCC_SYSCLKSOURCE_PLLCLK;
  RCC_ClkInitStruct.AHBCLKDivider = RCC_SYSCLK_DIV1;
  RCC_ClkInitStruct.APB1CLKDivider = RCC_HCLK_DIV4;
  RCC_ClkInitStruct.APB2CLKDivider = RCC_HCLK_DIV2;

  if (HAL_RCC_ClockConfig(&RCC_ClkInitStruct, FLASH_LATENCY_5) != HAL_OK)
  {
    Error_Handler();
  }

    /**Configure the Systick interrupt time
    */
  HAL_SYSTICK_Config(HAL_RCC_GetHCLKFreq()/1000);

    /**Configure the Systick
    */
  HAL_SYSTICK_CLKSourceConfig(SYSTICK_CLKSOURCE_HCLK);

  /* SysTick_IRQn interrupt configuration */
  HAL_NVIC_SetPriority(SysTick_IRQn, 0, 0);
}

/* USER CODE BEGIN 4 */
void Vonalszenzorkezeles_uartfogadas()
{
	  //UART uzenet fogadasa a vonalszenzortol
	  pozicio_elso = uzenetarray[0] + uzenetarray[1]*0xff;
	  pozicio_masodik = uzenetarray[2] + uzenetarray[3]*0xff;
	  vonaltipus=uzenetarray[4];
	  orientacio=pozicio_elso-pozicio_masodik;
	  //if(allapotteres_szabalyozo==NORMAL)
		//  allapotteres_szabalyozo_default(&pozicio_elso, &orientacio, &velocity, &szervoPWM);
	 // else if (allapotteres_szabalyozo==GYORSITO_SZAB)
		  allapotteres_szabalyozo_kanyar_kijarat(&pozicio_elso, &orientacio, &velocity, &szervoPWM);
	  __HAL_TIM_SET_COMPARE(&htim1, TIM_CHANNEL_2, szervoPWM);
	  vonalszenzor_uzenetjott=false;
}

void Motorkezeles()
{
	  if(((actualmotorinput < previousmotorinput) ? actualmotorinput : previousmotorinput) < 4000)
		  stop_deadman = true;
	  else
		  stop_deadman = false;
	  if (stop_cel || stop_safetycar)
		  stop = true;
	  else
		  stop = false;

	  if(timestamp > 500)
	  {
		  if (!stop)
			  __HAL_TIM_SET_COMPARE(&htim8, TIM_CHANNEL_3, motorpulsePWM);
		  else if (encoder_diff > 3)
			  __HAL_TIM_SET_COMPARE(&htim8, TIM_CHANNEL_3, 4000);
		  else
			  __HAL_TIM_SET_COMPARE(&htim8, TIM_CHANNEL_3, 6932);
	  }
}

void allapotteres_szabalyozo_kanyar_kijarat(uint16_t* pozicio, int16_t* orientacio, int32_t* sebesseg, uint32_t* PWMeredmeny)
{
	float sebesseg_a_szabalyozonak = 0.0;
	sebesseg_a_szabalyozonak=((float)*sebesseg)/1000.0; //[m/s]

	if(*sebesseg < 2000)
		//uj
		//*PWMeredmeny = (uint32_t) (-296.0805*(2*((float)*pozicio)-3300)/(1325.5776*(0.1143*sebesseg_a_szabalyozonak+0.8)*(0.1143*sebesseg_a_szabalyozonak+0.8))+(-0.441-0.18517*sebesseg_a_szabalyozonak)*atan_lut[*orientacio+2300]/((0.1143*sebesseg_a_szabalyozonak+0.8)*(0.1143*sebesseg_a_szabalyozonak+0.8))+5930);
		*PWMeredmeny = (uint32_t) (-296.0805*(2*((float)*pozicio)-3300)/(1325.5776*(0.1*sebesseg_a_szabalyozonak+0.95)*(0.1*sebesseg_a_szabalyozonak+0.95))+(-0.684-0.162*sebesseg_a_szabalyozonak)*atan_lut[*orientacio+2300]/((0.1*sebesseg_a_szabalyozonak+0.95)*(0.1*sebesseg_a_szabalyozonak+0.95))+5930);

		//lassu, kanyarkijarat
		//*PWMeredmeny = (uint32_t) (-296.0805*(2*((float)*pozicio)-3300)/(1325.5776*(0.11112*sebesseg_a_szabalyozonak+0.3981)*(0.11112*sebesseg_a_szabalyozonak+0.3981))+(0.21008-0.18001*sebesseg_a_szabalyozonak)*atan_lut[*orientacio+2300]/((0.11112*sebesseg_a_szabalyozonak+0.3981)*(0.11112*sebesseg_a_szabalyozonak+0.3981))+5930);
	else
		//uj
		*PWMeredmeny = (uint32_t) (-296.0805*(2*((float)*pozicio)-3300)/(1325.5776*(0.573*sebesseg_a_szabalyozonak+0.004)*(0.573*sebesseg_a_szabalyozonak+0.004))+(0.84852-0.92826*sebesseg_a_szabalyozonak)*atan_lut[*orientacio+2300]/((0.573*sebesseg_a_szabalyozonak+0.004)*(0.573*sebesseg_a_szabalyozonak+0.004))+5930);

		//gyors
		//*PWMeredmeny = (uint32_t) (-296.0805*(2*((float)*pozicio)-3300)/(1325.5776*(0.6568*sebesseg_a_szabalyozonak-0.284)*(0.6568*sebesseg_a_szabalyozonak-0.284))+(1.3151-1.064*sebesseg_a_szabalyozonak)*atan_lut[*orientacio+2300]/((00.6568*sebesseg_a_szabalyozonak-0.284)*(0.6568*sebesseg_a_szabalyozonak-0.284))+5930);

	if(*PWMeredmeny > 7250)
		*PWMeredmeny=7250;
	else if(*PWMeredmeny < 4610)
		*PWMeredmeny=4610;
}
void allapotteres_szabalyozo_default(uint16_t* pozicio, int16_t* orientacio, int32_t* sebesseg, uint32_t* PWMeredmeny)
{
	float sebesseg_a_szabalyozonak = 0.0;
	sebesseg_a_szabalyozonak=((float)*sebesseg)/1000.0; //[m/s]

	if(*sebesseg < 2000)
		//lassu, kanyar alatt
		*PWMeredmeny = (uint32_t) (-296.0805*(2*((float)*pozicio)-3300)/(1325.5776*(0.0857*sebesseg_a_szabalyozonak+0.85)*(0.0857*sebesseg_a_szabalyozonak+0.85))+(-0.522-0.13883*sebesseg_a_szabalyozonak)*atan_lut[*orientacio+2300]/((0.0857*sebesseg_a_szabalyozonak+0.85)*(0.0857*sebesseg_a_szabalyozonak+0.85))+5930);

	else
		//gyors
		*PWMeredmeny = (uint32_t) (-296.0805*(2*((float)*pozicio)-3300)/(1325.5776*(0.6167*sebesseg_a_szabalyozonak-0.0833)*(0.6167*sebesseg_a_szabalyozonak-0.0833))+(0.98995-0.99905*sebesseg_a_szabalyozonak)*atan_lut[*orientacio+2300]/((0.6167*sebesseg_a_szabalyozonak-0.0833)*(0.6167*sebesseg_a_szabalyozonak-0.0833))+5930);
	if(*PWMeredmeny > 7250)
		*PWMeredmeny=7250;
	else if(*PWMeredmeny < 4610)
		*PWMeredmeny=4610;
}
void WMAfilter(int32_t* filteredval, int32_t* newelement, int32_t* array, uint32_t filter_depth)
{
	*filteredval=0;
	int32_t coeffsum=0;

	for(int i=0; i<filter_depth-1; i++)
	{
		array[i]=array[i+1];
		*filteredval=*filteredval+array[i]*(i+1);
		coeffsum+=(i+1);
	}
	array[filter_depth-1]=*newelement;
	*filteredval=*filteredval+array[filter_depth-1]*(filter_depth);
	coeffsum+=(filter_depth);
	*filteredval=*filteredval/coeffsum;
}
void Encoder_beolvasas() //!!!Fix idokozonkent kell hivni, szamit ra a fuggveny (10ms)
{
	  encoder_state = HAL_TIM_Encoder_GetState(&htim2);
	  if(encoder_state==HAL_TIM_STATE_READY)
	  {
		  encoder_aktualis=actualencoderval*2;//valami rossza az enkoderrel, valszeg nem kapjuk meg az egyik channelt
		  encoder_diff=encoder_aktualis-encoder_elozo;
		  velocity=encoder_diff*10000/743;//velocity=((encoderdiff*10000)/743); //v[mm/s]
		  encoder_elozo=encoder_aktualis;
		  WMAfilter(&encoder_diff_WMA, &encoder_diff, encoder_diff_array, 4);
	  }
	  else
	  {
		  //error handling...
	  }
}
void Safety_car_old()
{
	static uint32_t stop_kezdete=0;
	if(SHARP_FRONT_filtered > 2000) //35cm
	{
		stop_safetycar=true;
		stop_kezdete=timestamp;
	}
	else if(SHARP_FRONT_filtered > 1200) //55cm
	{
		motorpulsePWM=7270;
	}
	else if(SHARP_FRONT_filtered > 800) //85cm
	{
		motorpulsePWM=7300;
	}
	else if(SHARP_FRONT_filtered < 600) //95cm
		motorpulsePWM=7360;

	if(SHARP_FRONT_filtered < 2000 && timestamp-stop_kezdete > 25)  //250 msig allunk
	{
		stop_safetycar=false;
	}
	if(pozicio_elso > 1900 || pozicio_elso < 1300) //Kanyari max sebesseg
		motorpulsePWM=7300;

	if((timestamp%10)==1)
	{
		/*sprintf(&string,"..........\r\n");
		sprintf(&string,"%d\t%d",SHARP_FRONT_filtered, velocity);
		HAL_UART_Transmit_DMA(&huart2, &string, sizeof(string)*sizeof(uint8_t));*/
	}
}

void Safety_car_P()
{
	mmpersec_sebesseg= (1400-((SHARP_FRONT_raw-600)*9)/7);
	if(mmpersec_sebesseg > 1400)
		mmpersec_sebesseg=1400;
	if(mmpersec_sebesseg < -100)
		mmpersec_sebesseg = -100;
	if(pozicio_elso > 1900 || pozicio_elso < 1300) //Kanyari max sebesseg
		mmpersec_sebesseg=600;
}

void sebessegszabalyozo(int32_t mmpersec)
{

	// Belso valtozok
	int32_t alapjel = mmpersec;
	static int32_t elozo_alapjel = 0;
	static float beavatkozo_jel = 0;
	static float elozo_beavatkozo_jel = 0;
	static float pozitiv_visszacsatolas = 0;
	float FOXBORO_bemeno_jel = 0;

	// Szabalyozas
	// Szabalyozasi algoritmus
	pozitiv_visszacsatolas = 0.99288*pozitiv_visszacsatolas+0.0071168*beavatkozo_jel;
	FOXBORO_bemeno_jel = 0.9029*(mmpersec-velocity)+pozitiv_visszacsatolas;
	// Beavatkozo szerv telites kezelese
	if(FOXBORO_bemeno_jel > 1500)
		beavatkozo_jel = 1500;
	else if(FOXBORO_bemeno_jel < -4000)
		beavatkozo_jel = -4000;
	else
		beavatkozo_jel = FOXBORO_bemeno_jel;
	// Inverz statikus nemlinearitas
	if(beavatkozo_jel > 0)
	{
		if((0 < beavatkozo_jel) && (beavatkozo_jel <= 112.0907))
			beavatkozo_jel = 200+0.89213*beavatkozo_jel;
		else if((112.0907 < beavatkozo_jel) && (beavatkozo_jel <= 350.2835))
			beavatkozo_jel = 300+0.41983*(beavatkozo_jel-112.0907);
		else if((350.2835 < beavatkozo_jel) && (beavatkozo_jel <= 560.4536))
			beavatkozo_jel = 400+0.47581*(beavatkozo_jel-350.2835);
		else if((560.4536 < beavatkozo_jel) && (beavatkozo_jel <= 756.6123))
			beavatkozo_jel = 500+0.50979*(beavatkozo_jel-560.4536);
		else if((756.6123 < beavatkozo_jel) && (beavatkozo_jel <= 910.737))
			beavatkozo_jel = 600+0.64883*(beavatkozo_jel-756.6123);
	}
	// Beavatkozo jel kiadasa
	motorpulsePWM = (uint32_t) (beavatkozo_jel+6932);
	// Integratorok feltoltese
	elozo_alapjel = alapjel;
	elozo_beavatkozo_jel = beavatkozo_jel;
}

void fekezo_sebessegszabalyozo(int32_t mmpersec)
{

	// Belso valtozok
	int32_t alapjel = mmpersec;
	static int32_t elozo_alapjel = 0;
	static float beavatkozo_jel = 0;
	static float elozo_beavatkozo_jel = 0;
	static float pozitiv_visszacsatolas = 0;
	float FOXBORO_bemeno_jel = 0;

	// Szabalyozas
	// Szabalyozasi algoritmus
	pozitiv_visszacsatolas = 0.99288*pozitiv_visszacsatolas+0.0071168*beavatkozo_jel;
	FOXBORO_bemeno_jel = 40.0*(mmpersec-velocity)+pozitiv_visszacsatolas;
	// Beavatkozo szerv telites kezelese
	if(FOXBORO_bemeno_jel > 1500)
		beavatkozo_jel = 1500;
	else if(FOXBORO_bemeno_jel < -4000)
		beavatkozo_jel = -4000;
	else
		beavatkozo_jel = FOXBORO_bemeno_jel;
	// Inverz statikus nemlinearitas
	if(beavatkozo_jel > 0)
	{
		if((0 < beavatkozo_jel) && (beavatkozo_jel <= 112.0907))
			beavatkozo_jel = 200+0.89213*beavatkozo_jel;
		else if((112.0907 < beavatkozo_jel) && (beavatkozo_jel <= 350.2835))
			beavatkozo_jel = 300+0.41983*(beavatkozo_jel-112.0907);
		else if((350.2835 < beavatkozo_jel) && (beavatkozo_jel <= 560.4536))
			beavatkozo_jel = 400+0.47581*(beavatkozo_jel-350.2835);
		else if((560.4536 < beavatkozo_jel) && (beavatkozo_jel <= 756.6123))
			beavatkozo_jel = 500+0.50979*(beavatkozo_jel-560.4536);
		else if((756.6123 < beavatkozo_jel) && (beavatkozo_jel <= 910.737))
			beavatkozo_jel = 600+0.64883*(beavatkozo_jel-756.6123);
	}
	// Beavatkozo jel kiadasa
	motorpulsePWM = (uint32_t) (beavatkozo_jel+6932);
	// Integratorok feltoltese
	elozo_alapjel = alapjel;
	elozo_beavatkozo_jel = beavatkozo_jel;
}

void vonalminta_felismeres()
{
	static bool vonalfigyeles_aktiv=false; //
	static int32_t startpozicio=0;
	static bool voltmaregyvonal=false;
	//static int32_t vonaleszleles_helye=0;
	static bool elso_belepes_lesz_egyvonalba=false;
	static bool elso_belepes_lesz_haromvonalba=true;
	static bool vonalfigyeles_ignoralva = false;
	static uint8_t haromvonalak_szama=0;
	static int32_t haromvonal_kezdete=0;
	static int32_t egyvonal_kezdete=0;

	//Legyen "volt egyvonal" valtozo -> akkor nem lehet lassito

	//bizonyos tavolsag utan mindenkepp kilepni, ha van eredmeny, ha nincs- done

	if(vonalfigyeles_ignoralva==true && (encoder_aktualis-startpozicio > 30000)) //4m utan figyeljuk csak ujra a vonalat
	{
		vonalfigyeles_ignoralva=false;
	}

	if(vonaltipus==HAROMVONAL && vonalfigyeles_aktiv==false && vonalfigyeles_ignoralva==false)
	{
		//csak akkor figyelunk vonalat, ha az elso 3 vonal legalabb 3cm
		if(startpozicio==0) //elso eset
		{
			startpozicio=encoder_aktualis;
		}
		if(encoder_aktualis-startpozicio > 150) //2cm utan elhisszuk hogy van jel
			vonalfigyeles_aktiv=true;
	}
	//startpoz-t nullazni kell ha nincs jel,
	if(vonaltipus==EGYVONAL && vonalfigyeles_aktiv==false && vonalfigyeles_ignoralva==false && startpozicio!=0 && encoder_aktualis-startpozicio > 150)  //2cm
		startpozicio=0;

	if(vonaltipus==HAROMVONAL && vonalfigyeles_aktiv==true && elso_belepes_lesz_haromvonalba==true)
		//Kell meg hosszfigyeles: csak 3cm utan fogadunk el objektumot
	{
		elso_belepes_lesz_haromvonalba=false;
		haromvonal_kezdete=encoder_aktualis;
	}
	if(vonaltipus==HAROMVONAL && vonalfigyeles_aktiv==true && elso_belepes_lesz_haromvonalba==false && encoder_aktualis-haromvonal_kezdete > 150 && haromvonal_kezdete!=0)//2cm
	{
		haromvonalak_szama++;
		elso_belepes_lesz_egyvonalba=true;
		haromvonal_kezdete=0;
	}

	if(vonaltipus==EGYVONAL && vonalfigyeles_aktiv==true && elso_belepes_lesz_egyvonalba==true)
		//Kell meg hosszfigyeles: csak 4cm utan fogadunk el objektumot
	{
		elso_belepes_lesz_egyvonalba=false;
		egyvonal_kezdete=encoder_aktualis;
		voltmaregyvonal=true;
	}
	if(vonaltipus==EGYVONAL && vonalfigyeles_aktiv==true && elso_belepes_lesz_egyvonalba==false && encoder_aktualis-egyvonal_kezdete > 150 && egyvonal_kezdete!=0) //2cm
	{
		elso_belepes_lesz_haromvonalba=true;
		egyvonal_kezdete=0;
	}

	if(vonaltipus==HAROMVONAL && vonalfigyeles_aktiv==true && encoder_aktualis-startpozicio > 1000 && haromvonalak_szama==1 && voltmaregyvonal==false) //legyen inkabb 13 cm //30cm - 2220 utan csak egy osszefuggo 3 vonal: lassito
	{
		vonalminta=LASSITO;
		//reset all
		vonalfigyeles_ignoralva=true;
		vonalfigyeles_aktiv=false;
		haromvonalak_szama=0;
		elso_belepes_lesz_egyvonalba=false;
		elso_belepes_lesz_haromvonalba=true;
		lassito_szakaszok_szama++;
		voltmaregyvonal=false;
		lassitora_mitcsinalunk();
	}

	else if(vonalfigyeles_aktiv==true && encoder_aktualis-startpozicio > 2823 && (haromvonalak_szama==3 || haromvonalak_szama==4) )//38 cm mulva 3 vonal
	{
		vonalminta=GYORSITO;
		//reste all
		vonalfigyeles_ignoralva=true;
		vonalfigyeles_aktiv=false;
		haromvonalak_szama=0;
		elso_belepes_lesz_egyvonalba=false;
		elso_belepes_lesz_haromvonalba=true;
		voltmaregyvonal=false;
		gyorsitora_mitcsinalunk();
	}
	else if (vonalfigyeles_aktiv==true && encoder_aktualis-startpozicio > 2823) //30cm mulva ha nincs semmi akkor exit
	{
		//vonalminta=SIMA_VEZETOVONAL;
		vonalfigyeles_aktiv=false;
		haromvonalak_szama=0;
		elso_belepes_lesz_egyvonalba=false;
		elso_belepes_lesz_haromvonalba=true;
		voltmaregyvonal=false;

	}
	/*else if(vonalfigyeles_aktiv==true && encoder_aktualis-startpozicio > 2823 && haromvonalak_szama<3 ) ez az else ag erzekeny a fugakra, ki kell venni
	{
		vonalminta=LASSITO;
		//reset all
		vonalfigyeles_ignoralva=true;
		vonalfigyeles_aktiv=false;
		haromvonalak_szama=0;
		elso_belepes_lesz_egyvonalba=false;
		elso_belepes_lesz_haromvonalba=true;
		lassito_szakaszok_szama++;
		lassitora_mitcsinalunk();
	}*/

}

void lassitora_mitcsinalunk()
{
	//mmpersec_sebesseg=1550;
	if(lassito_szakaszok_szama > 2)
		fekeztunk_mar=false;
	//allapotteres_szabalyozo=NORMAL;
}
void gyorsitora_mitcsinalunk()
{
	//allapotteres_szabalyozo=GYORSITO_SZAB;
	if(elso_gyorsito)
	{
		elso_gyorsito=false;
	}
	else
	{
		mmpersec_sebesseg=850;
		eltolt_gyorsulas=true;
	}

}
/* USER CODE END 4 */

void Error_Handler(void)
{
  while(1)
  {
  }
}

/************************ (C) COPYRIGHT STMicroelectronics *****END OF FILE****/
